VERSION ""

NS_ :

BS_:

BU_: ZCU_F LRCF PAM ZCU_CL
BO_ 1152 FD15_LRCF_DATA_5: 32 LRCF
 SG_ SMARTE_COAST_FR_TAR_DIST : 22|15@0+ (0.0078125,0) [0|255.9921875] "m" ZCU_CL,ZCU_F
 SG_ SMARTE_COAST_FR_TAR_CONFI : 55|2@0+ (1,0) [0|0] "" ZCU_CL,ZCU_F
 SG_ SMARTE_COAST_FR_REL_SPEED : 39|16@0+ (0.00390625,-128) [-128|127.99609375] "m/s" ZCU_CL,ZCU_F

BO_ 897 FD15_LRCF_DATA_6: 64 LRCF
 SG_ FRONT_CAMERA_RIGHTLINE_CURV_DERI : 23|16@0+ (4E-09,-0.000131072) [-0.000131072|0.000131060] "m-2" ZCU_CL
 SG_ FRONT_CAMERA_LEFTLINE_CURV_DERI : 39|16@0+ (4E-09,-0.000131072) [-0.000131072|0.000131060] "m-2" ZCU_CL
 SG_ FRONT_CAMERA_LEFTLINE_DISTANCE : 87|11@0+ (0.016,-16.384) [-16.384|16.336] "m" ZCU_CL
 SG_ FRONT_CAMERA_RIGHTLINE_DISTANCE : 92|11@0+ (0.016,-16.384) [-16.384|16.336] "m" ZCU_CL
 SG_ FRONT_CAMERA_LEFTLINE_CURVATURE : 55|16@0+ (2E-06,-0.065536) [-0.065536|0.065530] "m-1" ZCU_CL
 SG_ FRONT_CAMERA_RIGHTLINE_CURVATURE : 71|16@0+ (2E-06,-0.065536) [-0.065536|0.065530] "m-1" ZCU_CL
 SG_ FRONT_CAMERA_RIGHTLINE_DETECTION : 97|1@0+ (1,0) [0|0] "" ZCU_CL
 SG_ FRONT_CAMERA_LEFTLINE_DETECTION : 96|1@0+ (1,0) [0|0] "" ZCU_CL
 SG_ FRONT_CAMERA_LANE_STATUS : 111|2@0+ (1,0) [0|0] "" ZCU_CL
 SG_ GFHB_CAMERA_STATUS : 109|3@0+ (1,0) [0|0] "" ZCU_CL
 SG_ FRONT_CAM_RIGHT_LINE_TYPE : 106|3@0+ (1,0) [0|0] "" ZCU_CL
 SG_ FRONT_CAM_LEFT_LINE_TYPE : 119|3@0+ (1,0) [0|0] "" ZCU_CL
 SG_ FRONT_CAM_RIGHT_LINE_MARK_QLTY : 116|2@0+ (1,0) [0|0] "" ZCU_CL
 SG_ FRONT_CAM_LEFT_LINE_MARK_QLTY : 114|2@0+ (1,0) [0|0] "" ZCU_CL
 SG_ FRONT_CAM_LEFT_LINE_HEADING_ANG : 112|12@0+ (0.015,-30) [-30|31.425] "Degree" ZCU_CL
 SG_ FRONT_CAM_RIGHT_LINE_HEADING_ANG : 132|12@0+ (0.015,-30) [-30|31.425] "Degree" ZCU_CL
 SG_ FRONT_CAM_LEFT_LINE_VIEW_RNG_ST : 166|7@0+ (0.5,0) [0|63.5] "m" ZCU_CL
 SG_ FRONT_CAM_RIGHT_LINE_VIEW_RNG_ST : 175|7@0+ (0.5,0) [0|63.5] "m" ZCU_CL
 SG_ FRONT_CAM_LEFT_LINE_VIEW_RNG_EN : 136|9@0+ (0.5,0) [0|255.5] "m" ZCU_CL
 SG_ FRONT_CAM_RIGHT_LINE_VIEW_RNG_EN : 159|9@0+ (0.5,0) [0|255.5] "m" ZCU_CL
 SG_ FRONT_CAM_NEXT_LEFT_LINE_TYPE : 283|3@0+ (1,0) [0|0] "" ZCU_CL
 SG_ FRONT_CAM_NEXT_RIGHT_LINE_TYPE : 251|3@0+ (1,0) [0|0] "" ZCU_CL
 SG_ FRONTCAM_NEXTRIGHTLINE_CURV_DERI : 183|16@0+ (4E-09,-0.000131072) [-0.000131072|0.000131060] "m-2" ZCU_CL
 SG_ FRONTCAM_NEXTLEFTLINE_CURV_DERI : 199|16@0+ (4E-09,-0.000131072) [-0.000131072|0.000131060] "m-2" ZCU_CL
 SG_ FRONTCAM_NEXT_LEFTLINE_MARK_QLTY : 289|2@0+ (1,0) [0|0] "" ZCU_CL
 SG_ FRONTCAM_NEXTRIGHTLINE_MARKQLTY : 339|2@0+ (1,0) [0|0] "" ZCU_CL
 SG_ FRONT_CAM_RIGHT_LANE_DIRECTION : 306|2@0+ (1,0) [0|0] "" ZCU_CL
 SG_ FRONT_CAM_LEFT_LANE_DIRECTION : 308|2@0+ (1,0) [0|0] "" ZCU_CL
 SG_ FRONTCAM_NEXT_LEFTLINE_LAT_DIST : 351|6@0+ (0.5,-16) [-16|15.5] "m" ZCU_CL
 SG_ FRONTCAM_NEXT_RIGHTLINE_LAT_DIST : 295|6@0+ (0.5,-16) [-16|15.5] "m" ZCU_CL
 SG_ FRONTCAM_LEFTLINE_LAT_DIST : 329|6@0+ (0.5,-16) [-16|15.5] "m" ZCU_CL
 SG_ FRONTCAM_RIGHTLINE_LAT_DIST : 359|6@0+ (0.5,-16) [-16|15.5] "m" ZCU_CL
 SG_ FRONTCAM_NEXTRIGHTLINE_CURVESTM : 215|16@0+ (2E-06,-0.065536) [-0.065536|0.065530] "m-1" ZCU_CL
 SG_ FRONTCAM_NEXTLEFTLINE_CURVESTIM : 231|16@0+ (2E-06,-0.065536) [-0.065536|0.065530] "m-1" ZCU_CL
 SG_ FRONTCAM_NEXTLEFTLINE_HEAD_ANG : 247|12@0+ (0.015,-30) [-30|31.395] "Degree" ZCU_CL
 SG_ FRONTCAM_NEXTRIGHTLINE_HEAD_ANG : 279|12@0+ (0.015,-30) [-30|31.395] "Degree" ZCU_CL
 SG_ FRONTCAM_NXTLEFTLINE_VIEW_RNG_ST : 367|7@0+ (0.5,0) [0|63.5] "m" ZCU_CL
 SG_ FRONTCAM_NXTRIGHTLINE_VIEWRNG_ST : 391|7@0+ (0.5,0) [0|63.5] "m" ZCU_CL
 SG_ FRONTCAM_NXTLEFTLINE_VIEW_RNG_EN : 399|9@0+ (0.5,0) [0|255.5] "m" ZCU_CL
 SG_ FRONTCAM_NXTRIGHTLINE_VIEWRNG_EN : 495|9@0+ (0.5,0) [0|255.5] "m" ZCU_CL
 SG_ FRONTCAM_NXTLEFTLINE_ROAD_EDGE : 375|3@0+ (1,0) [0|0] "" ZCU_CL
 SG_ FRONTCAM_NXTRIGHTLINE_ROAD_EDGE : 372|3@0+ (1,0) [0|0] "" ZCU_CL
 SG_ FRONTCAM_LEFTLINE_ROAD_EDGE : 383|3@0+ (1,0) [0|0] "" ZCU_CL
 SG_ FRONTCAM_RIGHTLINE_ROAD_EDGE : 380|3@0+ (1,0) [0|0] "" ZCU_CL
 SG_ FRONTCAM_LEFTLANE_DETECTION : 320|1@0+ (1,0) [0|0] "" ZCU_CL
 SG_ FRONTCAM_RIGHTLANE_DETECTION : 312|1@0+ (1,0) [0|0] "" ZCU_CL
 SG_ FRONTCAM_RIGHTHIGHWAY_EXITCONFID : 327|7@0+ (0.01,0) [0|1.27] "%" ZCU_CL
 SG_ FRONTCAM_LEFT_HIGHWAY_EXITCONFID : 319|7@0+ (0.01,0) [0|1.27] "%" ZCU_CL
 SG_ FRONTCAM_LEFT_HIGHWAY_EXIT : 345|2@0+ (1,0) [0|0] "" ZCU_CL
 SG_ FRONTCAM_NXT_LEFTLINE_COLOR : 337|2@0+ (1,0) [0|0] "" ZCU_CL
 SG_ FRONTCAM_NXT_RIGHTTLINE_COLOR : 353|2@0+ (1,0) [0|0] "" ZCU_CL
 SG_ FRONTCAM_LEFTLINE_COLOR : 335|2@0+ (1,0) [0|0] "" ZCU_CL
 SG_ FRONTCAM_RIGHTTLINE_COLOR : 333|2@0+ (1,0) [0|0] "" ZCU_CL
 SG_ FRONTCAM_NXTLEFTLINE_DIST_ACTUAL : 303|11@0+ (0.016,-16.384) [-16.384|16.336] "" ZCU_CL
 SG_ FRONTCAM_NXTRIGHTLINE_DISTACTUAL : 479|11@0+ (0.016,-16.384) [-16.384|16.336] "" ZCU_CL
 SG_ FRONTCAM_NXT_LEFTLINE_DETECT_STS : 280|1@0+ (1,0) [0|0] "" ZCU_CL
 SG_ FRONTCAM_NXTRIGHTLINE_DETECT_STS : 168|1@0+ (1,0) [0|0] "" ZCU_CL
 SG_ FRONTCAM_LANE_CROSSING : 331|2@0+ (1,0) [0|0] "" ZCU_CL
 SG_ FRONTCAM_EGO_OBJ_CIPV : 304|1@0+ (1,0) [0|0] "" ZCU_CL
 SG_ FRONTCAM_EGO2_OBJ_CIPV : 360|1@0+ (1,0) [0|0] "" ZCU_CL
 SG_ FRONTCAM_L1_OBJ_CIPV : 368|1@0+ (1,0) [0|0] "" ZCU_CL
 SG_ FRONTCAM_L2_OBJ_CIPV : 376|1@0+ (1,0) [0|0] "" ZCU_CL
 SG_ FRONTCAM_L3_OBJ_CIPV : 384|1@0+ (1,0) [0|0] "" ZCU_CL
 SG_ FRONTCAM_R1_OBJ_CIPV : 369|1@0+ (1,0) [0|0] "" ZCU_CL
 SG_ FRONTCAM_R2_OBJ_CIPV : 377|1@0+ (1,0) [0|0] "" ZCU_CL
 SG_ FRONTCAM_R3_OBJ_CIPV : 248|1@0+ (1,0) [0|0] "" ZCU_CL
 SG_ FRONTCAM_EGO_OBJ_LONGI_DISTANCE : 415|8@0+ (0.5,0) [0|127.5] "m" ZCU_CL
 SG_ FRONTCAM_EGO2_OBJ_LONGI_DISTANCE : 423|8@0+ (0.5,0) [0|127.5] "m" ZCU_CL
 SG_ FRONTCAM_L1_OBJ_LONGI_DISTANCE : 431|8@0+ (0.5,0) [0|127.5] "m" ZCU_CL
 SG_ FRONTCAM_L2_OBJ_LONGI_DISTANCE : 439|8@0+ (0.5,0) [0|127.5] "m" ZCU_CL
 SG_ FRONTCAM_L3_OBJ_LONGI_DISTANCE : 447|8@0+ (0.5,0) [0|127.5] "m" ZCU_CL
 SG_ FRONTCAM_R1_OBJ_LONGI_DISTANCE : 455|8@0+ (0.5,0) [0|127.5] "m" ZCU_CL
 SG_ FRONTCAM_R2_OBJ_LONGI_DISTANCE : 463|8@0+ (0.5,0) [0|127.5] "m" ZCU_CL
 SG_ FRONTCAM_R3_OBJ_LONGI_DISTANCE : 471|8@0+ (0.5,0) [0|127.5] "m" ZCU_CL
 SG_ FRONTCAM_EGO_OBJ_LAT_REL_SPD : 502|7@0+ (0.5,-32) [-32|31.5] "m/s" ZCU_CL
 SG_ FRONTCAM_EGO2_OBJ_LAT_REL_SPD : 406|7@0+ (0.5,-32) [-32|31.5] "m/s" ZCU_CL
 SG_ FRONTCAM_L1_OBJ_LAT_REL_SPD : 511|7@0+ (0.5,-32) [-32|31.5] "m/s" ZCU_CL

BO_ 640 FD15_LRCF_DATA_7: 64 LRCF
 SG_ VHL_1_CL_SUB_TYPE : 7|4@0+ (1,0) [0|0] "" ZCU_CL
 SG_ VHL_4_CL_SUB_TYPE : 11|4@0+ (1,0) [0|0] "" ZCU_CL
 SG_ VHL_5_CL_SUB_TYPE : 23|4@0+ (1,0) [0|0] "" ZCU_CL
 SG_ VHL_2_CL_SUB_TYPE : 3|4@0+ (1,0) [0|0] "" ZCU_CL
 SG_ VHL_3_CL_SUB_TYPE : 15|4@0+ (1,0) [0|0] "" ZCU_CL
 SG_ VHL_1_TYPE : 19|3@0+ (1,0) [0|0] "" ZCU_CL
 SG_ VHL_2_TYPE : 16|3@0+ (1,0) [0|0] "" ZCU_CL
 SG_ VHL_3_TYPE : 29|3@0+ (1,0) [0|0] "" ZCU_CL
 SG_ VHL_4_TYPE : 26|3@0+ (1,0) [0|0] "" ZCU_CL
 SG_ VHL_5_TYPE : 39|3@0+ (1,0) [0|0] "" ZCU_CL
 SG_ VHL_3_LEFT_ANGLE : 56|14@0+ (0.01,-60) [-60|103.81] "Degree" ZCU_CL
 SG_ VHL_1_LEFT_ANGLE : 36|14@0+ (0.01,-60) [-60|103.81] "Degree" ZCU_CL
 SG_ VHL_2_LEFT_ANGLE : 54|14@0+ (0.01,-60) [-60|103.81] "Degree" ZCU_CL
 SG_ VHL_4_LEFT_ANGLE : 74|14@0+ (0.01,-60) [-60|103.81] "Degree" ZCU_CL
 SG_ VHL_5_LEFT_ANGLE : 92|14@0+ (0.01,-60) [-60|103.81] "Degree" ZCU_CL
 SG_ VHL_1_BOTTOM_ANGLE : 168|14@0+ (0.01,-60) [-60|103.81] "Degree" ZCU_CL
 SG_ VHL_2_BOTTOM_ANGLE : 186|14@0+ (0.01,-60) [-60|103.81] "Degree" ZCU_CL
 SG_ VHL_3_BOTTOM_ANGLE : 204|14@0+ (0.01,-60) [-60|103.81] "Degree" ZCU_CL
 SG_ VHL_4_BOTTOM_ANGLE : 222|14@0+ (0.01,-60) [-60|103.81] "Degree" ZCU_CL
 SG_ VHL_5_BOTTOM_ANGLE : 224|14@0+ (0.01,-60) [-60|103.81] "Degree" ZCU_CL
 SG_ VHL_1_RIGHT_ANGLE : 110|14@0+ (0.01,-60) [-60|103.81] "Degree" ZCU_CL
 SG_ VHL_2_RIGHT_ANGLE : 112|14@0+ (0.01,-60) [-60|103.81] "Degree" ZCU_CL
 SG_ VHL_3_RIGHT_ANGLE : 130|14@0+ (0.01,-60) [-60|103.81] "Degree" ZCU_CL
 SG_ VHL_4_RIGHT_ANGLE : 148|14@0+ (0.01,-60) [-60|103.81] "Degree" ZCU_CL
 SG_ VHL_5_RIGHT_ANGLE : 166|14@0+ (0.01,-60) [-60|103.81] "Degree" ZCU_CL
 SG_ VHL_1_LEFT_DISTANCE : 242|10@0+ (1,2) [2|1023] "m" ZCU_CL
 SG_ VHL_2_LEFT_DISTANCE : 248|10@0+ (1,2) [2|1023] "m" ZCU_CL
 SG_ VHL_3_LEFT_DISTANCE : 270|10@0+ (1,2) [2|1023] "m" ZCU_CL
 SG_ VHL_4_LEFT_DISTANCE : 276|10@0+ (1,2) [2|1023] "m" ZCU_CL
 SG_ VHL_5_LEFT_DISTANCE : 282|10@0+ (1,2) [2|1023] "m" ZCU_CL
 SG_ VHL_1_RIGHT_DISTANCE : 288|10@0+ (1,2) [2|1023] "m" ZCU_CL
 SG_ VHL_2_RIGHT_DISTANCE : 310|10@0+ (1,2) [2|1023] "m" ZCU_CL
 SG_ VHL_3_RIGHT_DISTANCE : 316|10@0+ (1,2) [2|1023] "m" ZCU_CL
 SG_ VHL_4_RIGHT_DISTANCE : 322|10@0+ (1,2) [2|1023] "m" ZCU_CL
 SG_ VHL_5_RIGHT_DISTANCE : 328|10@0+ (1,2) [2|1023] "m" ZCU_CL
 SG_ VHL_1_RIGHT_AZIMUTH_RATE : 350|12@0+ (0.125,-128) [-128|383.625] "Degree/s" ZCU_CL
 SG_ VHL_2_RIGHT_AZIMUTH_RATE : 354|12@0+ (0.125,-128) [-128|383.625] "Degree/s" ZCU_CL
 SG_ VHL_3_RIGHT_AZIMUTH_RATE : 374|12@0+ (0.125,-128) [-128|383.625] "Degree/s" ZCU_CL
 SG_ VHL_4_RIGHT_AZIMUTH_RATE : 378|12@0+ (0.125,-128) [-128|383.625] "Degree/s" ZCU_CL
 SG_ VHL_5_RIGHT_AZIMUTH_RATE : 398|12@0+ (0.125,-128) [-128|383.625] "Degree/s" ZCU_CL
 SG_ VHL_1_LEFT_AZIMUTH_RATE : 402|12@0+ (0.125,-128) [-128|383.625] "Degree/s" ZCU_CL
 SG_ VHL_2_LEFT_AZIMUTH_RATE : 422|12@0+ (0.125,-128) [-128|383.625] "Degree/s" ZCU_CL
 SG_ VHL_3_LEFT_AZIMUTH_RATE : 426|12@0+ (0.125,-128) [-128|383.625] "Degree/s" ZCU_CL

BO_ 642 FD15_LRCF_DATA_8: 64 LRCF
 SG_ TRAFFIC_IS_DETECTED : 261|2@0+ (1,0) [0|0] "" ZCU_CL
 SG_ RFL_1_BRIGHTNESS : 7|7@0+ (0.01,0) [0|1.25] "" ZCU_CL
 SG_ RFL_2_BRIGHTNESS : 0|7@0+ (0.01,0) [0|1.25] "" ZCU_CL
 SG_ RFL_3_BRIGHTNESS : 9|7@0+ (0.01,0) [0|1.25] "" ZCU_CL
 SG_ RFL_1_TOP_ANGLE : 18|11@0+ (0.01,-10) [-10|10.45] "Degree" ZCU_CL
 SG_ RFL_2_TOP_ANGLE : 39|11@0+ (0.01,-10) [-10|10.45] "Degree" ZCU_CL
 SG_ RFL_3_TOP_ANGLE : 44|11@0+ (0.01,-10) [-10|10.45] "Degree" ZCU_CL
 SG_ RFL_1_BOTTOM_ANGLE : 49|11@0+ (0.01,-10) [-10|10.45] "Degree" ZCU_CL
 SG_ RFL_2_BOTTOM_ANGLE : 70|11@0+ (0.01,-10) [-10|10.45] "Degree" ZCU_CL
 SG_ RFL_3_BOTTOM_ANGLE : 75|11@0+ (0.01,-10) [-10|10.45] "Degree" ZCU_CL
 SG_ VHL_1_MIN_DISTANCE : 259|10@0+ (1,2) [2|1023] "m" ZCU_CL
 SG_ VHL_2_MIN_DISTANCE : 265|10@0+ (1,2) [2|1023] "m" ZCU_CL
 SG_ VHL_3_MIN_DISTANCE : 287|10@0+ (1,2) [2|1023] "m" ZCU_CL
 SG_ VHL_4_MIN_DISTANCE : 293|10@0+ (1,2) [2|1023] "m" ZCU_CL
 SG_ VHL_5_MIN_DISTANCE : 299|10@0+ (1,2) [2|1023] "m" ZCU_CL
 SG_ VHL_4_LEFT_AZIMUTH_RATE : 423|12@0+ (0.125,-128) [-128|383.625] "Degree/s" ZCU_CL
 SG_ VHL_5_LEFT_AZIMUTH_RATE : 427|12@0+ (0.125,-128) [-128|383.625] "Degree/s" ZCU_CL
 SG_ RFL_1_RIGHT_ANGLE : 80|13@0+ (0.01,-40) [-40|41.89] "Degree" ZCU_CL
 SG_ RFL_2_RIGHT_ANGLE : 99|13@0+ (0.01,-40) [-40|41.89] "Degree" ZCU_CL
 SG_ RFL_3_RIGHT_ANGLE : 118|13@0+ (0.01,-40) [-40|41.89] "Degree" ZCU_CL
 SG_ RFL_1_LEFT_ANGLE : 121|13@0+ (0.01,-40) [-40|41.89] "Degree" ZCU_CL
 SG_ RFL_2_LEFT_ANGLE : 140|13@0+ (0.01,-40) [-40|41.89] "Degree" ZCU_CL
 SG_ RFL_3_LEFT_ANGLE : 159|13@0+ (0.01,-40) [-40|41.89] "Degree" ZCU_CL
 SG_ RFL_1_LEFT_AZIMUTH_RATE : 193|11@0+ (0.05,-50) [-50|52.25] "Degree/s" ZCU_CL
 SG_ RFL_2_LEFT_AZIMUTH_RATE : 214|11@0+ (0.05,-50) [-50|52.25] "Degree/s" ZCU_CL
 SG_ RFL_3_LEFT_AZIMUTH_RATE : 219|11@0+ (0.05,-50) [-50|52.25] "Degree/s" ZCU_CL
 SG_ RFL_1_RIGHT_AZIMUTH_RATE : 162|11@0+ (0.05,-50) [-50|52.25] "Degree/s" ZCU_CL
 SG_ RFL_2_RIGHT_AZIMUTH_RATE : 183|11@0+ (0.05,-50) [-50|52.25] "Degree/s" ZCU_CL
 SG_ RFL_3_RIGHT_AZIMUTH_RATE : 188|11@0+ (0.05,-50) [-50|52.25] "Degree/s" ZCU_CL
 SG_ RFL_3_DISTANCE : 254|9@0+ (1,0) [0|509] "m" ZCU_CL
 SG_ RFL_2_DISTANCE : 247|9@0+ (1,0) [0|509] "m" ZCU_CL
 SG_ RFL_1_DISTANCE : 224|9@0+ (1,0) [0|509] "m" ZCU_CL
 SG_ VHL_1_VDID : 319|8@0+ (1,0) [0|255] "" ZCU_CL
 SG_ VHL_2_VDID : 327|8@0+ (1,0) [0|255] "" ZCU_CL
 SG_ VHL_3_VDID : 335|8@0+ (1,0) [0|255] "" ZCU_CL
 SG_ VHL_4_VDID : 343|8@0+ (1,0) [0|255] "" ZCU_CL
 SG_ VHL_5_VDID : 351|8@0+ (1,0) [0|255] "" ZCU_CL
 SG_ VHL_1_ID : 359|8@0+ (1,0) [0|255] "" ZCU_CL
 SG_ VHL_2_ID : 367|8@0+ (1,0) [0|255] "" ZCU_CL
 SG_ VHL_3_ID : 375|8@0+ (1,0) [0|255] "" ZCU_CL
 SG_ VHL_4_ID : 383|8@0+ (1,0) [0|255] "" ZCU_CL
 SG_ VHL_5_ID : 391|8@0+ (1,0) [0|255] "" ZCU_CL
 SG_ RFL_1_ID : 399|8@0+ (1,0) [0|255] "" ZCU_CL
 SG_ RFL_2_ID : 407|8@0+ (1,0) [0|255] "" ZCU_CL
 SG_ RFL_3_ID : 415|8@0+ (1,0) [0|255] "" ZCU_CL

BO_ 645 FD15_LRCF_DATA_9: 64 LRCF
 SG_ FREE_4 : 15|4@0+ (1,0) [0|0] "" ZCU_CL
 SG_ ACC_FRONT_TARGET_DISTANCE : 23|15@0+ (0.01,0) [0|327.67] "m" ZCU_CL
 SG_ ACC_ACCEL_SETPOINT_REQ : 24|11@0+ (0.01,-11) [-11|9.47] "m/s2" ZCU_CL
 SG_ ACC_FRONT_TARGET_RELARIVE_ACCEL : 92|12@0+ (0.008,-16) [-16|16.76] "m/s2" ZCU_CL
 SG_ ACC_FRONT_TARGET_RELARIVE_SPEED : 62|14@0+ (0.008,-60) [-60|71.064] "m/s2" ZCU_CL
 SG_ ACC_DESIRED_INTERVEHICLE_DIST : 45|15@0+ (0.008,0) [0|262.128] "m" ZCU_CL
 SG_ ACC_FRONT_TARGET_CRITICITY : 79|7@0+ (0.01,0) [0|1.27] "" ZCU_CL
 SG_ ACC_FRONT_TARGET_POSITION : 87|6@0+ (1,0) [0|0] "" ZCU_CL
 SG_ ACC_FRONT_TARGET_TYPE : 95|3@0+ (1,0) [0|0] "" ZCU_CL
 SG_ E2E_CRC_LRCF_DATA_9 : 7|8@0+ (1,0) [0|0] "-" ZCU_CL
 SG_ E2E_ALIVE_LRCF_DATA_9 : 11|4@0+ (1,0) [0|15] "-" ZCU_CL
 SG_ EGO_LANE_WIDTH : 111|10@0+ (0.01,0) [0|10.23] "m" ZCU_CL
 SG_ EGO_LANE_NUMBER : 141|2@0+ (1,0) [0|0] "" ZCU_CL
 SG_ FRONT_EGO_LANE_LOWER_LIMIT : 117|12@0+ (0.1,0) [0|409.5] "m" ZCU_CL
 SG_ FRONT_EGO_LANE_UPPER_LIMIT : 121|12@0+ (0.1,0) [0|409.5] "m" ZCU_CL
 SG_ EGO_LANE_QUALITY : 139|2@0+ (1,0) [0|0] "" ZCU_CL
 SG_ FRONT_EGO_LANE_A0_POLY_COEF : 137|37@0+ (7.45058E-09,-256) [-256|767.99991795196318] "" ZCU_CL
 SG_ FRONT_EGO_LANE_A1_POLY_COEF : 180|37@0+ (7.45058E-09,-256) [-256|767.99991795196318] "" ZCU_CL
 SG_ FRONT_EGO_LANE_A2_POLY_COEF : 223|37@0+ (7.45058E-09,-256) [-256|767.99991795196318] "" ZCU_CL
 SG_ FRONT_EGO_LANE_A3_POLY_COEF : 279|37@0+ (7.45058E-09,-256) [-256|767.99991795196318] "" ZCU_CL

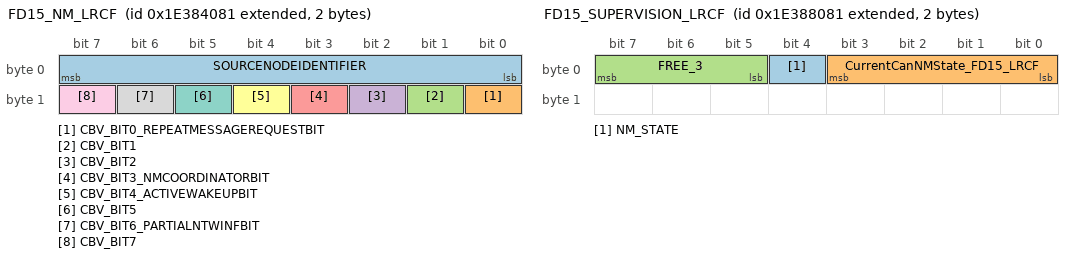
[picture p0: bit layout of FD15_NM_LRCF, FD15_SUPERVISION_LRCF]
BO_ 2654486657 FD15_NM_LRCF: 2 LRCF
 SG_ SOURCENODEIDENTIFIER : 7|8@0+ (1,0) [0|255] "No Unit" ZCU_CL,ZCU_F
 SG_ CBV_BIT0_REPEATMESSAGEREQUESTBIT : 8|1@0+ (1,0) [0|1] "No Unit" ZCU_CL,ZCU_F
 SG_ CBV_BIT1 : 9|1@0+ (1,0) [0|1] "No Unit" ZCU_CL,ZCU_F
 SG_ CBV_BIT2 : 10|1@0+ (1,0) [0|1] "No Unit" ZCU_CL,ZCU_F
 SG_ CBV_BIT3_NMCOORDINATORBIT : 11|1@0+ (1,0) [0|1] "No Unit" ZCU_CL,ZCU_F
 SG_ CBV_BIT4_ACTIVEWAKEUPBIT : 12|1@0+ (1,0) [0|1] "No Unit" ZCU_CL,ZCU_F
 SG_ CBV_BIT5 : 13|1@0+ (1,0) [0|1] "No Unit" ZCU_CL,ZCU_F
 SG_ CBV_BIT6_PARTIALNTWINFBIT : 14|1@0+ (1,0) [0|1] "No Unit" ZCU_CL,ZCU_F
 SG_ CBV_BIT7 : 15|1@0+ (1,0) [0|1] "No Unit" ZCU_CL,ZCU_F

BO_ 282 FD15_ORC_DATA_1: 32 ZCU_CL
 SG_ E2E_ALIVE_ORC_DATA_1_11A : 11|4@0+ (1,0) [0|15] "-" LRCF
 SG_ E2E_CRC_ORC_DATA_1_11A : 7|8@0+ (1,0) [0|0] "-" LRCF
 SG_ LAT_ACCELERATION_FAULT_STS : 50|1@0+ (1,0) [0|0] "" LRCF
 SG_ LONG_ACCELERATION_FAULT_STS : 51|1@0+ (1,0) [0|0] "" LRCF
 SG_ YAW_RATE_FAULT_STS : 49|1@0+ (1,0) [0|0] "" LRCF
 SG_ YAW_RATE : 23|12@0+ (0.08,-163.84) [-163.84|163.68] "Degree/s" LRCF
 SG_ LAT_ACCELERATION : 27|12@0+ (0.02,-40.96) [-40.96|40.92] "m/s2" LRCF
 SG_ LONG_ACCELERATION : 47|12@0+ (0.02,-40.96) [-40.96|40.92] "m/s2" LRCF

BO_ 2654339201 FD15_PDC_INFO_FD_LRCF: 1 LRCF
 SG_ EOL_LRCF : 7|1@0+ (1,0) [0|1] "-" ZCU_CL
 SG_ CurrentCanNMState_FD15_LRCF : 6|4@0+ (1,0) [0|15] "" ZCU_CL

BO_ 2654503041 FD15_SUPERVISION_LRCF: 2 LRCF
 SG_ NM_STATE : 4|1@0+ (1,0) [0|0] "-" ZCU_F
 SG_ CurrentCanNMState_FD15_LRCF : 3|4@0+ (1,0) [0|15] "" ZCU_F
 SG_ FREE_3 : 7|3@0+ (1,0) [0|0] "" ZCU_F

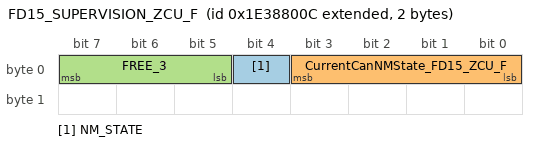
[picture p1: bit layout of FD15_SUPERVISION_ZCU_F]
BO_ 2654502924 FD15_SUPERVISION_ZCU_F: 2 ZCU_F
 SG_ NM_STATE : 4|1@0+ (1,0) [0|0] "-" LRCF,PAM,ZCU_CL
 SG_ CurrentCanNMState_FD15_ZCU_F : 3|4@0+ (1,0) [0|15] "" LRCF,PAM,ZCU_CL
 SG_ FREE_3 : 7|3@0+ (1,0) [0|0] "" LRCF,PAM,ZCU_CL

BO_ 129 FD15_VERS_LRCF: 1 LRCF
 SG_ VERSION_DATA : 7|8@0+ (1,0) [0|255] "" Vector__XXX

BO_ 121 FD15_ZCU_CL_ACK_EVT_DEF: 16 ZCU_CL
 SG_ ECU_Code_ACK : 15|8@0+ (1,0) [0|255] "" LRCF,PAM
 SG_ Rep_UCE : 7|1@0+ (1,0) [0|1] "" LRCF,PAM

BO_ 556 FD15_ZCU_CL_DATA_39: 32 ZCU_CL
 SG_ ACC_STATE_INFO_FOR_CHASSIS : 25|2@0+ (1,0) [0|0] "" LRCF
 SG_ LANE_ASSIT_STATE_FROM_LAS : 28|3@0+ (1,0) [0|0] "" LRCF
 SG_ TORQUE_FACTOR_REQUEST_FROM_LAS : 39|7@0+ (0.01,0) [0|1] "" LRCF
 SG_ YAW_RATE_REQUEST_SETPOINT_LAS : 23|11@0+ (0.05,0) [-50|50] "Degree/s" LRCF
 SG_ PACC_ACCEL_LONGI_REQUEST : 47|10@0+ (0.01,-5) [-5|5.23] "m/s2" LRCF
 SG_ PACC_BEVENT_IN_PROGRESS : 32|1@0+ (1,0) [0|0] "" LRCF

BO_ 1546 FD15_ZCU_CL_DATA_4: 32 ZCU_CL
 SG_ DRIVER_DOOR_OPEN_STATUS : 25|1@0+ (1,0) [0|0] "" LRCF,PAM,ZCU_F
 SG_ EXT_TEMP_FILTRED_DEG_C : 23|10@0+ (0.5,-85) [-85|425.5] "Degree C" LRCF,PAM,ZCU_F
 SG_ HEADLAMP_WITH_WIPER_REQ : 27|1@0+ (1,0) [0|0] "" LRCF,PAM,ZCU_F
 SG_ TRAILER_CONNECTION_STS : 29|2@0+ (1,0) [0|0] "" LRCF,PAM,ZCU_F
 SG_ RCTA_DRIVER_INHIBITION_REQUEST : 24|1@0+ (1,0) [0|0] "" LRCF,PAM,ZCU_F
 SG_ PASSENGER_DOOR_OPEN_STATUS : 26|1@0+ (1,0) [0|0] "" LRCF,PAM,ZCU_F
 SG_ TURN_SIGNAL_STS : 38|2@0+ (1,0) [0|0] "" LRCF,PAM,ZCU_F
 SG_ DAY_NIGHT_STATUS : 39|1@0+ (1,0) [0|0] "" LRCF,PAM,ZCU_F
 SG_ FRONT_WIPING_ST : 35|5@0+ (1,0) [0|0] "" LRCF,PAM,ZCU_F
 SG_ FRT_WIPING_CONF : 46|1@0+ (1,0) [0|0] "" LRCF,PAM,ZCU_F
 SG_ DRIVING_MODE_POWERTRAIN_REQ : 45|5@0+ (1,0) [0|0] "" LRCF,PAM,ZCU_F

BO_ 1032 FD15_ZCU_CL_DATA_7: 32 ZCU_CL
 SG_ DRIVER_SEATBELT_BUCKLE_DATA : 23|1@0+ (1,0) [0|0] "" LRCF,PAM
 SG_ DRIVER_SEATBELT_BUCKLE_SECU_DATA : 22|2@0+ (1,0) [0|0] "" LRCF,PAM
 SG_ ROW1_P_SEATBELT_BUCKLE_DATA : 20|1@0+ (1,0) [0|0] "" LRCF,PAM
 SG_ ROW1_P_SEATBELT_BUCKLE_SECU_DATA : 19|2@0+ (1,0) [0|0] "" LRCF,PAM
 SG_ TURN_INDICATOR_DRIVER_DMD : 17|2@0+ (1,0) [0|0] "" LRCF,PAM
 SG_ VIN_INFORMATION : 31|136@0+ (1,0) [0|0] "" LRCF,PAM

BO_ 1289 FD15_ZCU_CL_DATA_9: 32 ZCU_CL
 SG_ BLINDSPOTDETECTION_DRIVERREQUEST : 23|1@0+ (1,0) [0|0] "" LRCF,PAM

BO_ 1034 FD15_ZCU_CL_GLOBAL_DATA_1: 32 ZCU_CL
 SG_ FREE_4 : 15|4@0+ (1,0) [0|0] "" LRCF,PAM
 SG_ VEHICLE_IGNITION_STATUS : 23|3@0+ (1,0) [0|0] "" LRCF,PAM
 SG_ PROPULSION_OFF_REQUEST : 20|1@0+ (1,0) [0|0] "" LRCF,PAM
 SG_ VEHICLE_MODE_CONFIGURATION : 19|4@0+ (1,0) [0|0] "" LRCF,PAM
 SG_ E2E_CRC_ZCU_CL_GLOBAL_DATA_40A : 7|8@0+ (1,0) [0|0] "-" LRCF,PAM
 SG_ E2E_ALIVE_ZCU_CL_GLOBAL_DATA_40A : 11|4@0+ (1,0) [0|15] "-" LRCF,PAM
 SG_ DAY_LIGHT_MODE_CMD : 39|1@0+ (1,0) [0|0] "" LRCF,PAM
 SG_ BACK_LIGHT_INTENSITY_CMD : 31|8@0+ (0.5,0) [0|127.5] "%" LRCF,PAM

BO_ 1550 FD15_ZCU_F_DATA_15: 32 ZCU_F
 SG_ ESC_TCS_FAILSTATUS : 23|1@0+ (1,0) [0|0] "" LRCF
 SG_ FREE_4 : 15|4@0+ (1,0) [0|0] "" LRCF
 SG_ WHEEL_SPARE_SIZEDETECTION_STATE : 22|1@0+ (1,0) [0|0] "" LRCF
 SG_ E2E_CRC_ZCU_F_DATA_15 : 7|8@0+ (1,0) [0|0] "-" LRCF
 SG_ E2E_ALIVE_ZCU_F_DATA_15 : 11|4@0+ (1,0) [0|15] "" LRCF

BO_ 1055 FD15_ZCU_F_DATA_17: 32 ZCU_F
 SG_ HOD_FAIL_STATUS : 23|2@0+ (1,0) [0|0] "" LRCF
 SG_ STEERWHEEL_HELD_BY_DRIVER_OPTI : 21|1@0+ (1,0) [0|0] "" LRCF

BO_ 270 FD15_ZCU_F_DATA_9: 32 ZCU_F
 SG_ FREE_4 : 15|4@0+ (1,0) [0|0] "" LRCF,PAM,ZCU_CL
 SG_ ACCEL_PEDAL_PERCENT_PWT : 23|8@0+ (0.4,0) [0|101.6] "%" LRCF,PAM,ZCU_CL
 SG_ PRND_ENGAGED_FOR_DISPLAY : 100|5@0+ (1,0) [0|0] "" LRCF,PAM,ZCU_CL
 SG_ PRND_TARGET_STATE : 91|4@0+ (1,0) [0|0] "" LRCF,PAM,ZCU_CL
 SG_ SHIFT_LEVER_POSITION_PWT : 31|4@0+ (1,0) [0|0] "" LRCF,PAM,ZCU_CL
 SG_ E2E_CRC_ZCU_F_DATA_9 : 7|8@0+ (1,0) [0|0] "-" LRCF,PAM,ZCU_CL
 SG_ E2E_ALIVE_ZCU_F_DATA_9 : 11|4@0+ (1,0) [0|15] "-" LRCF,PAM,ZCU_CL
 SG_ HANDWHEEL_STEERING_ANGLE_VALUE_S : 47|14@0+ (0.1,-820) [-820|818.2] "Degree" LRCF,PAM,ZCU_CL
 SG_ LXA_STEERING_STATE_S : 49|2@0+ (1,0) [0|0] "" LRCF,PAM,ZCU_CL
 SG_ STEERING_ASSIST_STATUS_S : 94|3@0+ (1,0) [0|0] "" LRCF,PAM,ZCU_CL
 SG_ STEERINGWHEEL_ANGLE_REL_FRT_VA_S : 63|15@0+ (0.1,-1638) [-1638|1638.6] "Degree" LRCF,PAM,ZCU_CL
 SG_ STEERINGWHEEL_ROT_VELOCITY_FRT_S : 27|12@0+ (1,-2050) [-2050|2044] "Degree/s" LRCF,PAM,ZCU_CL
 SG_ ACC_STATE_INFO_IN_POWERTRAIN : 103|3@0+ (1,0) [0|0] "" LRCF,PAM,ZCU_CL
 SG_ STEERINGWHEEL_ANGLE_FRONT_VAL_S : 79|14@0+ (0.1,-820) [-820|818.2] "Degree" LRCF,PAM,ZCU_CL
 SG_ CRUISE_CONTROL_STATUS : 111|3@0+ (1,0) [0|7] "" LRCF,PAM,ZCU_CL

BO_ 1035 FD15_ZCU_F_GLOBAL_DATA_2: 32 ZCU_F
 SG_ FREE_4 : 15|4@0+ (1,0) [0|0] "" LRCF,PAM
 SG_ PROPULSION_SYSTEM_ACTIVE : 47|1@0+ (1,0) [0|0] "" LRCF,PAM
 SG_ E2E_CRC_ZCU_F_GLOBAL_DATA : 7|8@0+ (1,0) [0|0] "-" LRCF,PAM
 SG_ E2E_ALIVE_ZCU_F_GLOBAL_DATA_40B : 11|4@0+ (1,0) [0|15] "-" LRCF,PAM
 SG_ TOTAL_ODOMETER : 23|24@0+ (0.1,0) [0|1677721.4] "km" LRCF,PAM
 SG_ DIAGMUX : 46|1@0+ (1,0) [0|0] "" LRCF,PAM
 SG_ TRUSTED_TIME_YEAR : 55|16@0+ (1,0) [0|65534] "Year" LRCF,PAM
 SG_ TRUSTED_TIME_MONTH : 71|4@0+ (1,1) [1|15] "month" LRCF,PAM
 SG_ TRUSTED_TIME_DAY : 79|5@0+ (1,1) [1|31] "day" LRCF,PAM
 SG_ TRUSTED_TIME_HOUR : 87|5@0+ (1,0) [0|30] "hour" LRCF,PAM
 SG_ TRUSTED_TIME_MINUTE : 45|6@0+ (1,0) [0|62] "min" LRCF,PAM
 SG_ TRUSTED_TIME_SECOND : 95|6@0+ (1,0) [0|62] "" LRCF,PAM
 SG_ SHUTDOWN_NTW_FD_CAN14 : 67|1@0+ (1,0) [0|0] "" Vector__XXX
 SG_ SHUTDOWN_NTW_FD_CAN5 : 66|1@0+ (1,0) [0|0] "" Vector__XXX

CM_ SG_ 1152 SMARTE_COAST_FR_TAR_DIST "Longitudinal distance of the Ecaosting target in the host vehicle's coordinate system";
CM_ SG_ 1152 SMARTE_COAST_FR_TAR_CONFI "Confidence of Ecaosting target.";
CM_ SG_ 1152 SMARTE_COAST_FR_REL_SPEED "Relative longitudinal velocity of the Ecaosting target in the host vehicle's coordinate system.";
CM_ SG_ 897 FRONT_CAMERA_RIGHTLINE_CURV_DERI "Curvature derivative of right lane marking";
CM_ SG_ 897 FRONT_CAMERA_LEFTLINE_CURV_DERI "Curvature derivative of left lane marking";
CM_ SG_ 897 FRONT_CAMERA_RIGHTLINE_DETECTION "Validity-flag for detection of the road's right line  according to line history, contrast, lane coherence,  view range, camera-state and lane width changes";
CM_ SG_ 897 FRONT_CAMERA_LEFTLINE_DETECTION "Validity-flag for detection of the road's left line  according to line history, contrast, lane coherence,  view range, camera-state and lane width changes";
CM_ SG_ 897 FRONT_CAMERA_LANE_STATUS "Overall status of the FrontCamera 
(fully operational, blocked, degraded, defect)";
CM_ SG_ 897 GFHB_CAMERA_STATUS "Defines the status of  GFHB function";
CM_ SG_ 897 FRONT_CAM_RIGHT_LINE_MARK_QLTY "Quality of right host lane’s line marking";
CM_ SG_ 897 FRONT_CAM_LEFT_LINE_MARK_QLTY "Quality of left host lane’s line marking";
CM_ SG_ 897 FRONT_CAM_NEXT_LEFT_LINE_TYPE "This signal indicates the type of the next left ego line marking";
CM_ SG_ 897 FRONT_CAM_NEXT_RIGHT_LINE_TYPE "This signal indicates the type of the next right ego line marking";
CM_ SG_ 897 FRONTCAM_NEXTRIGHTLINE_CURV_DERI "Derivative of left line marking curvature  (Polynomial C3, unit: 1/m^2)";
CM_ SG_ 897 FRONTCAM_NEXTLEFTLINE_CURV_DERI "Derivative of left line marking curvature  (Polynomial C3, unit: 1/m^2)";
CM_ SG_ 897 FRONTCAM_NEXT_LEFTLINE_MARK_QLTY "Quality of next right host lane’s line marking";
CM_ SG_ 897 FRONTCAM_NEXTRIGHTLINE_MARKQLTY "Quality of next right host lane’s line marking";
CM_ SG_ 897 FRONT_CAM_RIGHT_LANE_DIRECTION "This signal indicates the direction of the right lane";
CM_ SG_ 897 FRONT_CAM_LEFT_LANE_DIRECTION "This signal indicates the direction of the right lane";
CM_ SG_ 897 FRONTCAM_NEXT_LEFTLINE_LAT_DIST "Lateral distance of the next left (considering the inner part of the line) line with respect to the Forward-Facing Camera coordinate system";
CM_ SG_ 897 FRONTCAM_NEXT_RIGHTLINE_LAT_DIST "Lateral distance of the next right (considering the inner part of the line) line with respect to the Forward-Facing Camera coordinate system";
CM_ SG_ 897 FRONTCAM_LEFTLINE_LAT_DIST "Lateral distance of the first left (considering the inner part of the line) line with respect to the Forward-Facing Camera coordinate system";
CM_ SG_ 897 FRONTCAM_RIGHTLINE_LAT_DIST "Lateral distance of the first right (considering the inner part of the line) line with respect to the Forward-Facing Camera coordinate system";
CM_ SG_ 897 FRONTCAM_NEXTRIGHTLINE_CURVESTM "Estimated curvature of next right line marking (Polynomial C2, unit: 1/m)";
CM_ SG_ 897 FRONTCAM_NEXTLEFTLINE_CURVESTIM "Estimated curvature of next left line marking (Polynomial C2, unit: 1/m)";
CM_ SG_ 897 FRONTCAM_NEXTLEFTLINE_HEAD_ANG "C1: Heading angle of vehicle with the  next left line (angle between vehicle direction and lane limit direction, unit: ° (deg))";
CM_ SG_ 897 FRONTCAM_NEXTRIGHTLINE_HEAD_ANG "C1: Heading angle of vehicle with the  next left line (angle between vehicle direction and lane limit direction, unit: ° (deg))";
CM_ SG_ 897 FRONTCAM_NXTLEFTLINE_VIEW_RNG_ST "Next left host lane’s line marking View Range starts at this distance";
CM_ SG_ 897 FRONTCAM_NXTRIGHTLINE_VIEWRNG_ST "Next right Left host lane’s line marking View Range starts at this distance";
CM_ SG_ 897 FRONTCAM_NXTLEFTLINE_VIEW_RNG_EN "Next left host lane’s line marking View Range ends at this distance";
CM_ SG_ 897 FRONTCAM_NXTRIGHTLINE_VIEWRNG_EN "Next right Left host lane’s line marking View Range ends at this distance";
CM_ SG_ 897 FRONTCAM_NXTLEFTLINE_ROAD_EDGE "Next Left Line roadedge  :  Flat =  transition from asphalt to grass or gravel Elevated_Structure =Higher objects like road bariers) Curb : Generally curbs with different colors and sizes Cones_poles : All kinds of road cones Parking_cars=Cars parked in a line on the side of the road No_Roadedge";
CM_ SG_ 897 FRONTCAM_NXTRIGHTLINE_ROAD_EDGE "Next Right Line roadedge  :  Flat =  transition from asphalt to grass or gravel Elevated_Structure =Higher objects like road bariers) Curb : Generally curbs with different colors and sizes Cones_poles : All kinds of road cones Parking_cars=Cars parked in a line on the side of the road No_Roadedge";
CM_ SG_ 897 FRONTCAM_LEFTLINE_ROAD_EDGE "Left Line roadedge  :  Flat =  transition from asphalt to grass or gravel Elevated_Structure =Higher objects like road bariers) Curb : Generally curbs with different colors and sizes Cones_poles : All kinds of road cones Parking_cars=Cars parked in a line on the side of the road No_Roadedge";
CM_ SG_ 897 FRONTCAM_RIGHTLINE_ROAD_EDGE "Right Line roadedge  :  Flat =  transition from asphalt to grass or gravel Elevated_Structure =Higher objects like road bariers) Curb : Generally curbs with different colors and sizes Cones_poles : All kinds of road cones Parking_cars=Cars parked in a line on the side of the road No_Roadedge";
CM_ SG_ 897 FRONTCAM_LEFTLANE_DETECTION "This signal indicates if a lane  is detected at the left of the host vehicle.";
CM_ SG_ 897 FRONTCAM_RIGHTLANE_DETECTION "This signal indicates if a lane  is detected at the right of the host vehicle.";
CM_ SG_ 897 FRONTCAM_RIGHTHIGHWAY_EXITCONFID "Confidence of detection of left highway exit";
CM_ SG_ 897 FRONTCAM_LEFT_HIGHWAY_EXITCONFID "Confidence of detection of left highway exit";
CM_ SG_ 897 FRONTCAM_LEFT_HIGHWAY_EXIT "Highway exit (HWE) can only be detected on one side at a time";
CM_ SG_ 897 FRONTCAM_NXT_LEFTLINE_COLOR "Color of the Next Left line";
CM_ SG_ 897 FRONTCAM_NXT_RIGHTTLINE_COLOR "Color of the Next right line";
CM_ SG_ 897 FRONTCAM_LEFTLINE_COLOR "Color of the Next right line";
CM_ SG_ 897 FRONTCAM_RIGHTTLINE_COLOR "Color of the right line";
CM_ SG_ 897 FRONTCAM_NXTLEFTLINE_DIST_ACTUAL "Front camera center to inner edge next left line (C0 parameter of line equation)";
CM_ SG_ 897 FRONTCAM_NXTRIGHTLINE_DISTACTUAL "Distance: Center of the vehicle to inner edge  of the road's next right line (Polynomial C0)";
CM_ SG_ 897 FRONTCAM_NXT_LEFTLINE_DETECT_STS "Validity-flag for detection of the road's next left line  according to line history, contrast, lane coherence,  view range, camera-state and lane width changes";
CM_ SG_ 897 FRONTCAM_NXTRIGHTLINE_DETECT_STS "Validity-flag for detection of the road's next right line  according to line history, contrast, lane coherence,  view range, camera-state and lane width changes";
CM_ SG_ 897 FRONTCAM_LANE_CROSSING "This flow indicates if the ego change the lane on the left or right side.";
CM_ SG_ 897 FRONTCAM_EGO_OBJ_CIPV "This is the boolean flag that indicates which target the ACC feature reacts to. (four target could be considered 1st front, 2nd front 3rd or 4th while using overtake aid)";
CM_ SG_ 897 FRONTCAM_EGO2_OBJ_CIPV "This is the boolean flag that indicates which target the ACC feature reacts to. (four target could be considered 1st front, 2nd front 3rd or 4th while using overtake aid)";
CM_ SG_ 897 FRONTCAM_L1_OBJ_CIPV "This is the boolean flag that indicates which target the ACC feature reacts to. (four target could be considered 1st front, 2nd front 3rd or 4th while using overtake aid)";
CM_ SG_ 897 FRONTCAM_L2_OBJ_CIPV "This is the boolean flag that indicates which target the ACC feature reacts to. (four target could be considered 1st front, 2nd front 3rd or 4th while using overtake aid)";
CM_ SG_ 897 FRONTCAM_L3_OBJ_CIPV "This is the boolean flag that indicates which target the ACC feature reacts to. (four target could be considered 1st front, 2nd front 3rd or 4th while using overtake aid)";
CM_ SG_ 897 FRONTCAM_R1_OBJ_CIPV "This is the boolean flag that indicates which target the ACC feature reacts to. (four target could be considered 1st front, 2nd front 3rd or 4th while using overtake aid)";
CM_ SG_ 897 FRONTCAM_R2_OBJ_CIPV "This is the boolean flag that indicates which target the ACC feature reacts to. (four target could be considered 1st front, 2nd front 3rd or 4th while using overtake aid)";
CM_ SG_ 897 FRONTCAM_R3_OBJ_CIPV "This is the boolean flag that indicates which target the ACC feature reacts to. (four target could be considered 1st front, 2nd front 3rd or 4th while using overtake aid)";
CM_ SG_ 897 FRONTCAM_EGO_OBJ_LONGI_DISTANCE "Longitudinal distance of the ego objects target with respect to the Forward-Facing Camera coordinate system";
CM_ SG_ 897 FRONTCAM_EGO2_OBJ_LONGI_DISTANCE "Longitudinal distance of the second ego objects target  with respect to the Forward-Facing Camera coordinate system";
CM_ SG_ 897 FRONTCAM_L1_OBJ_LONGI_DISTANCE "Longitudinal distance of the first target on the left side lane  with respect to the Forward-Facing Camera coordinate system";
CM_ SG_ 897 FRONTCAM_L2_OBJ_LONGI_DISTANCE "Longitudinal distance of second target on the left side lane with respect to the Forward-Facing Camera coordinate system";
CM_ SG_ 897 FRONTCAM_L3_OBJ_LONGI_DISTANCE "Longitudinal distance third target on the left side lane with respect to the Forward-Facing Camera coordinate system";
CM_ SG_ 897 FRONTCAM_R1_OBJ_LONGI_DISTANCE "Longitudinal distance of the first target on the right side lane  with respect to the Forward-Facing Camera coordinate system";
CM_ SG_ 897 FRONTCAM_R2_OBJ_LONGI_DISTANCE "Longitudinal distance of the second target on the right side lane  with respect to the Forward-Facing Camera coordinate system";
CM_ SG_ 897 FRONTCAM_R3_OBJ_LONGI_DISTANCE "Longitudinal distance third target on the right side lane with respect to the Forward-Facing Camera coordinate system";
CM_ SG_ 897 FRONTCAM_EGO_OBJ_LAT_REL_SPD "Relative lateral velocity of Measured Target Front with respect to host vehicle";
CM_ SG_ 897 FRONTCAM_EGO2_OBJ_LAT_REL_SPD "Relative lateral velocity of Measured Second Target Front with respect to host vehicle";
CM_ SG_ 897 FRONTCAM_L1_OBJ_LAT_REL_SPD "Relative lateral velocity of Measured Target L1 Front with respect to host vehicle";
CM_ SG_ 640 VHL_1_CL_SUB_TYPE "ENUM describes cluster sub type. If not cluster = 0
Indicates if the cluster of vehicles is mixing oncoming and/or leading vehicles, or not.
INVALID : object is not a cluster
ONCOMING : All objects are oncoming
TAILLIGHT : All objects are leading
LEFT_ONCOMING: Most left object is oncoming, others are leading.
RIGHT_ONCOMING: Most right object is oncoming, others are leading.
LEFT_AND_RIGHT_ONCOMING: Leading objects between most left and right.
LEFT_AND_RIGHT_TAILLIGHT: Oncoming objects between most left and right.
Invalid
Unavailable";
CM_ SG_ 640 VHL_4_CL_SUB_TYPE "ENUM describes cluster sub type. If not cluster = 0
Indicates if the cluster of vehicles is mixing oncoming and/or leading vehicles, or not.
INVALID : object is not a cluster
ONCOMING : All objects are oncoming
TAILLIGHT : All objects are leading
LEFT_ONCOMING: Most left object is oncoming, others are leading.
RIGHT_ONCOMING: Most right object is oncoming, others are leading.
LEFT_AND_RIGHT_ONCOMING: Leading objects between most left and right.
LEFT_AND_RIGHT_TAILLIGHT: Oncoming objects between most left and right.
Invalid
Unavailable";
CM_ SG_ 640 VHL_5_CL_SUB_TYPE "ENUM describes cluster sub type. If not cluster = 0
Indicates if the cluster of vehicles is mixing oncoming and/or leading vehicles, or not.
INVALID : object is not a cluster
ONCOMING : All objects are oncoming
TAILLIGHT : All objects are leading
LEFT_ONCOMING: Most left object is oncoming, others are leading.
RIGHT_ONCOMING: Most right object is oncoming, others are leading.
LEFT_AND_RIGHT_ONCOMING: Leading objects between most left and right.
LEFT_AND_RIGHT_TAILLIGHT: Oncoming objects between most left and right.
Invalid
Unavailable";
CM_ SG_ 640 VHL_2_CL_SUB_TYPE "ENUM describes cluster sub type. If not cluster = 0
Indicates if the cluster of vehicles is mixing oncoming and/or leading vehicles, or not.
INVALID : object is not a cluster
ONCOMING : All objects are oncoming
TAILLIGHT : All objects are leading
LEFT_ONCOMING: Most left object is oncoming, others are leading.
RIGHT_ONCOMING: Most right object is oncoming, others are leading.
LEFT_AND_RIGHT_ONCOMING: Leading objects between most left and right.
LEFT_AND_RIGHT_TAILLIGHT: Oncoming objects between most left and right.
Invalid
Unavailable";
CM_ SG_ 640 VHL_3_CL_SUB_TYPE "ENUM describes cluster sub type. If not cluster = 0
Indicates if the cluster of vehicles is mixing oncoming and/or leading vehicles, or not.
INVALID : object is not a cluster
ONCOMING : All objects are oncoming
TAILLIGHT : All objects are leading
LEFT_ONCOMING: Most left object is oncoming, others are leading.
RIGHT_ONCOMING: Most right object is oncoming, others are leading.
LEFT_AND_RIGHT_ONCOMING: Leading objects between most left and right.
LEFT_AND_RIGHT_TAILLIGHT: Oncoming objects between most left and right.
Invalid
Unavailable";
CM_ SG_ 640 VHL_1_TYPE "Describes the vehicle light type detected. Indicates oncoming or leading vehicle  In case of a cluster it represents the type of the closest vehicle in the cluster. Clearance = Truck cabin top lights (i.e. oncoming).";
CM_ SG_ 640 VHL_2_TYPE "Describes the vehicle light type detected. Indicates oncoming or leading vehicle  In case of a cluster it represents the type of the closest vehicle in the cluster. Clearance = Truck cabin top lights (i.e. oncoming).";
CM_ SG_ 640 VHL_3_TYPE "Describes the vehicle light type detected. Indicates oncoming or leading vehicle  In case of a cluster it represents the type of the closest vehicle in the cluster. Clearance = Truck cabin top lights (i.e. oncoming).";
CM_ SG_ 640 VHL_4_TYPE "Describes the vehicle light type detected. Indicates oncoming or leading vehicle  In case of a cluster it represents the type of the closest vehicle in the cluster. Clearance = Truck cabin top lights (i.e. oncoming).";
CM_ SG_ 640 VHL_5_TYPE "Describes the vehicle light type detected. Indicates oncoming or leading vehicle  In case of a cluster it represents the type of the closest vehicle in the cluster. Clearance = Truck cabin top lights (i.e. oncoming).";
CM_ SG_ 640 VHL_3_LEFT_ANGLE "Horizontal angle at the Left tail light or headlamp of vehicle detected at the extreme Left of the cluster (oncoming or leading), by a camera having at least +/-50deg of horizontal field of view. This angle is calculated from the camera reference.";
CM_ SG_ 640 VHL_1_LEFT_ANGLE "Horizontal angle at the Left tail light or headlamp of vehicle detected at the extreme Left of the cluster (oncoming or leading), by a camera having at least +/-50deg of horizontal field of view. This angle is calculated from the camera reference.";
CM_ SG_ 640 VHL_2_LEFT_ANGLE "Horizontal angle at the Left tail light or headlamp of vehicle detected at the extreme Left of the cluster (oncoming or leading), by a camera having at least +/-50deg of horizontal field of view. This angle is calculated from the camera reference.";
CM_ SG_ 640 VHL_4_LEFT_ANGLE "Horizontal angle at the Left tail light or headlamp of vehicle detected at the extreme Left of the cluster (oncoming or leading), by a camera having at least +/-50deg of horizontal field of view. This angle is calculated from the camera reference.";
CM_ SG_ 640 VHL_5_LEFT_ANGLE "Horizontal angle at the Left tail light or headlamp of vehicle detected at the extreme Left of the cluster (oncoming or leading), by a camera having at least +/-50deg of horizontal field of view. This angle is calculated from the camera reference.";
CM_ SG_ 640 VHL_1_BOTTOM_ANGLE "Vertical Angle to bottom of the closest / lowest vehicle lights in the cluster rectangle including object lights. This angle is calculated from the camera reference.";
CM_ SG_ 640 VHL_2_BOTTOM_ANGLE "Vertical Angle to bottom of the closest / lowest vehicle lights in the cluster rectangle including object lights. This angle is calculated from the camera reference.";
CM_ SG_ 640 VHL_3_BOTTOM_ANGLE "Vertical Angle to bottom of the closest / lowest vehicle lights in the cluster rectangle including object lights. This angle is calculated from the camera reference.";
CM_ SG_ 640 VHL_4_BOTTOM_ANGLE "Vertical Angle to bottom of the closest / lowest vehicle lights in the cluster rectangle including object lights. This angle is calculated from the camera reference.";
CM_ SG_ 640 VHL_5_BOTTOM_ANGLE "Vertical Angle to bottom of the closest / lowest vehicle lights in the cluster rectangle including object lights. This angle is calculated from the camera reference.";
CM_ SG_ 640 VHL_1_RIGHT_ANGLE "Horizontal angle at the Right tail light or headlamp of vehicle detected at the extreme Right of the cluster (oncoming or leading), by a camera having at least +/-50deg of horizontal field of view. This angle is calculated from the camera reference.";
CM_ SG_ 640 VHL_2_RIGHT_ANGLE "Horizontal angle at the Right tail light or headlamp of vehicle detected at the extreme Right of the cluster (oncoming or leading), by a camera having at least +/-50deg of horizontal field of view. This angle is calculated from the camera reference.";
CM_ SG_ 640 VHL_3_RIGHT_ANGLE "Horizontal angle at the Right tail light or headlamp of vehicle detected at the extreme Right of the cluster (oncoming or leading), by a camera having at least +/-50deg of horizontal field of view. This angle is calculated from the camera reference.";
CM_ SG_ 640 VHL_4_RIGHT_ANGLE "Horizontal angle at the Right tail light or headlamp of vehicle detected at the extreme Right of the cluster (oncoming or leading), by a camera having at least +/-50deg of horizontal field of view. This angle is calculated from the camera reference.";
CM_ SG_ 640 VHL_5_RIGHT_ANGLE "Horizontal angle at the Right tail light or headlamp of vehicle detected at the extreme Right of the cluster (oncoming or leading), by a camera having at least +/-50deg of horizontal field of view. This angle is calculated from the camera reference.";
CM_ SG_ 640 VHL_1_LEFT_DISTANCE "Horizontal minimum distance to the extreme left vehicle detected in the cluster 2.";
CM_ SG_ 640 VHL_2_LEFT_DISTANCE "Horizontal minimum distance to the extreme left vehicle detected in the cluster 2.";
CM_ SG_ 640 VHL_3_LEFT_DISTANCE "Horizontal minimum distance to the extreme left vehicle detected in the cluster 2.";
CM_ SG_ 640 VHL_4_LEFT_DISTANCE "Horizontal minimum distance to the extreme left vehicle detected in the cluster 2.";
CM_ SG_ 640 VHL_5_LEFT_DISTANCE "Horizontal minimum distance to the extreme left vehicle detected in the cluster 2.";
CM_ SG_ 640 VHL_1_RIGHT_DISTANCE "Horizontal minimum distance to the extreme Right vehicle detected in the cluster 1.";
CM_ SG_ 640 VHL_2_RIGHT_DISTANCE "Horizontal minimum distance to the extreme Right vehicle detected in the cluster 1.";
CM_ SG_ 640 VHL_3_RIGHT_DISTANCE "Horizontal minimum distance to the extreme Right vehicle detected in the cluster 1.";
CM_ SG_ 640 VHL_4_RIGHT_DISTANCE "Horizontal minimum distance to the extreme Right vehicle detected in the cluster 1.";
CM_ SG_ 640 VHL_5_RIGHT_DISTANCE "Horizontal minimum distance to the extreme Right vehicle detected in the cluster 1.";
CM_ SG_ 640 VHL_1_RIGHT_AZIMUTH_RATE "Horizontal relative azimuth angular velocity of the Right side of vehicle detected at the extreme Left of the cluster. It is calculated in the camera coordinates system. The ego-vehicle yaw rate value is deducted from the measured relative azimuth rate value and then shall be added downstream.  Due to this, the signal is not strictly, a derivative of the corresponding angular coordinate.";
CM_ SG_ 640 VHL_2_RIGHT_AZIMUTH_RATE "Horizontal relative azimuth angular velocity of the Right side of vehicle detected at the extreme Left of the cluster. It is calculated in the camera coordinates system. The ego-vehicle yaw rate value is deducted from the measured relative azimuth rate value and then shall be added downstream.  Due to this, the signal is not strictly, a derivative of the corresponding angular coordinate.";
CM_ SG_ 640 VHL_3_RIGHT_AZIMUTH_RATE "Horizontal relative azimuth angular velocity of the Right side of vehicle detected at the extreme Left of the cluster. It is calculated in the camera coordinates system. The ego-vehicle yaw rate value is deducted from the measured relative azimuth rate value and then shall be added downstream.  Due to this, the signal is not strictly, a derivative of the corresponding angular coordinate.";
CM_ SG_ 640 VHL_4_RIGHT_AZIMUTH_RATE "Horizontal relative azimuth angular velocity of the Right side of vehicle detected at the extreme Left of the cluster. It is calculated in the camera coordinates system. The ego-vehicle yaw rate value is deducted from the measured relative azimuth rate value and then shall be added downstream.  Due to this, the signal is not strictly, a derivative of the corresponding angular coordinate.";
CM_ SG_ 640 VHL_5_RIGHT_AZIMUTH_RATE "Horizontal relative azimuth angular velocity of the Right side of vehicle detected at the extreme Left of the cluster. It is calculated in the camera coordinates system. The ego-vehicle yaw rate value is deducted from the measured relative azimuth rate value and then shall be added downstream.  Due to this, the signal is not strictly, a derivative of the corresponding angular coordinate.";
CM_ SG_ 640 VHL_1_LEFT_AZIMUTH_RATE "Horizontal relative azimuth angular velocity of the Left side of vehicle detected at the extreme Left of the cluster. It is calculated in the camera coordinates system. The ego-vehicle yaw rate value is deducted from the measured relative azimuth rate value and then shall be added downstream.  Due to this, the signal is not strictly, a derivative of the corresponding angular coordinate.";
CM_ SG_ 640 VHL_2_LEFT_AZIMUTH_RATE "Horizontal relative azimuth angular velocity of the Left side of vehicle detected at the extreme Left of the cluster. It is calculated in the camera coordinates system. The ego-vehicle yaw rate value is deducted from the measured relative azimuth rate value and then shall be added downstream.  Due to this, the signal is not strictly, a derivative of the corresponding angular coordinate.";
CM_ SG_ 640 VHL_3_LEFT_AZIMUTH_RATE "Horizontal relative azimuth angular velocity of the Left side of vehicle detected at the extreme Left of the cluster. It is calculated in the camera coordinates system. The ego-vehicle yaw rate value is deducted from the measured relative azimuth rate value and then shall be added downstream.  Due to this, the signal is not strictly, a derivative of the corresponding angular coordinate.";
CM_ SG_ 642 TRAFFIC_IS_DETECTED "Indicates if at least one vehicle object (oncoming, oncoming clearance, leading or side) is detected in front of the ego-vehicle.";
CM_ SG_ 642 RFL_1_BRIGHTNESS "The brightness of the reflector object.";
CM_ SG_ 642 RFL_2_BRIGHTNESS "The brightness of the reflector object.";
CM_ SG_ 642 RFL_3_BRIGHTNESS "The brightness of the reflector object.";
CM_ SG_ 642 RFL_1_TOP_ANGLE "Angle to top of the reflector object";
CM_ SG_ 642 RFL_2_TOP_ANGLE "Angle to top of the reflector object";
CM_ SG_ 642 RFL_3_TOP_ANGLE "Angle to top of the reflector object";
CM_ SG_ 642 RFL_1_BOTTOM_ANGLE "Angle to bottom of the reflector object";
CM_ SG_ 642 RFL_2_BOTTOM_ANGLE "Angle to bottom of the reflector object";
CM_ SG_ 642 RFL_3_BOTTOM_ANGLE "Angle to bottom of the reflector object";
CM_ SG_ 642 VHL_1_MIN_DISTANCE "Horizontal minimum distance to the closest vehicle detected in the cluster 1.";
CM_ SG_ 642 VHL_2_MIN_DISTANCE "Horizontal minimum distance to the closest vehicle detected in the cluster 1.";
CM_ SG_ 642 VHL_3_MIN_DISTANCE "Horizontal minimum distance to the closest vehicle detected in the cluster 1.";
CM_ SG_ 642 VHL_4_MIN_DISTANCE "Horizontal minimum distance to the closest vehicle detected in the cluster 1.";
CM_ SG_ 642 VHL_5_MIN_DISTANCE "Horizontal minimum distance to the closest vehicle detected in the cluster 1.";
CM_ SG_ 642 VHL_4_LEFT_AZIMUTH_RATE "Horizontal relative azimuth angular velocity of the Left side of vehicle detected at the extreme Left of the cluster. It is calculated in the camera coordinates system. The ego-vehicle yaw rate value is deducted from the measured relative azimuth rate value and then shall be added downstream.  Due to this, the signal is not strictly, a derivative of the corresponding angular coordinate.";
CM_ SG_ 642 VHL_5_LEFT_AZIMUTH_RATE "Horizontal relative azimuth angular velocity of the Left side of vehicle detected at the extreme Left of the cluster. It is calculated in the camera coordinates system. The ego-vehicle yaw rate value is deducted from the measured relative azimuth rate value and then shall be added downstream.  Due to this, the signal is not strictly, a derivative of the corresponding angular coordinate.";
CM_ SG_ 642 RFL_1_RIGHT_ANGLE "Angle to Right of the reflector object";
CM_ SG_ 642 RFL_2_RIGHT_ANGLE "Angle to Right of the reflector object";
CM_ SG_ 642 RFL_3_RIGHT_ANGLE "Angle to Right of the reflector object";
CM_ SG_ 642 RFL_1_LEFT_ANGLE "Angle to left of the reflector object";
CM_ SG_ 642 RFL_2_LEFT_ANGLE "Angle to left of the reflector object";
CM_ SG_ 642 RFL_3_LEFT_ANGLE "Angle to left of the reflector object";
CM_ SG_ 642 RFL_1_LEFT_AZIMUTH_RATE "Horizontal relative azimuth angular velocity of the left side of reflector object <n>. It is calculated in the camera coordinates system camera coordinates system. The ego-vehicle yaw rate value is deducted from the measured relative azimuth rate value and then shall be added downstream.  Due to this, the signal is not strictly, a derivative of the corresponding angular coordinate. ";
CM_ SG_ 642 RFL_2_LEFT_AZIMUTH_RATE "Horizontal relative azimuth angular velocity of the left side of reflector object <n>. It is calculated in the camera coordinates system camera coordinates system. The ego-vehicle yaw rate value is deducted from the measured relative azimuth rate value and then shall be added downstream.  Due to this, the signal is not strictly, a derivative of the corresponding angular coordinate. ";
CM_ SG_ 642 RFL_3_LEFT_AZIMUTH_RATE "Horizontal relative azimuth angular velocity of the left side of reflector object <n>. It is calculated in the camera coordinates system camera coordinates system. The ego-vehicle yaw rate value is deducted from the measured relative azimuth rate value and then shall be added downstream.  Due to this, the signal is not strictly, a derivative of the corresponding angular coordinate. ";
CM_ SG_ 642 RFL_1_RIGHT_AZIMUTH_RATE "Horizontal relative azimuth angular velocity of the right side of reflector object <X>. It is calculated in the camera coordinates system camera coordinates system. The ego-vehicle yaw rate value is deducted from the measured relative azimuth rate value and then shall be added downstream.  Due to this, the signal is not strictly, a derivative of the corresponding angular coordinate.";
CM_ SG_ 642 RFL_2_RIGHT_AZIMUTH_RATE "Horizontal relative azimuth angular velocity of the right side of reflector object <X>. It is calculated in the camera coordinates system camera coordinates system. The ego-vehicle yaw rate value is deducted from the measured relative azimuth rate value and then shall be added downstream.  Due to this, the signal is not strictly, a derivative of the corresponding angular coordinate.";
CM_ SG_ 642 RFL_3_RIGHT_AZIMUTH_RATE "Horizontal relative azimuth angular velocity of the right side of reflector object <X>. It is calculated in the camera coordinates system camera coordinates system. The ego-vehicle yaw rate value is deducted from the measured relative azimuth rate value and then shall be added downstream.  Due to this, the signal is not strictly, a derivative of the corresponding angular coordinate.";
CM_ SG_ 642 RFL_3_DISTANCE "Distance to reflector object";
CM_ SG_ 642 RFL_2_DISTANCE "Distance to reflector object";
CM_ SG_ 642 RFL_1_DISTANCE "Distance to reflector object";
CM_ SG_ 642 VHL_1_VDID "to define if the detection of the vehicle object <X> is taking into account the fusion between LSV (light rectangle) and 3DVD (3D bounding box detection) or Not. Description to be reviewed with ME";
CM_ SG_ 642 VHL_2_VDID "to define if the detection of the vehicle object <X> is taking into account the fusion between LSV (light rectangle) and 3DVD (3D bounding box detection) or Not. Description to be reviewed with ME";
CM_ SG_ 642 VHL_3_VDID "to define if the detection of the vehicle object <X> is taking into account the fusion between LSV (light rectangle) and 3DVD (3D bounding box detection) or Not. Description to be reviewed with ME";
CM_ SG_ 642 VHL_4_VDID "to define if the detection of the vehicle object <X> is taking into account the fusion between LSV (light rectangle) and 3DVD (3D bounding box detection) or Not. Description to be reviewed with ME";
CM_ SG_ 642 VHL_5_VDID "to define if the detection of the vehicle object <X> is taking into account the fusion between LSV (light rectangle) and 3DVD (3D bounding box detection) or Not. Description to be reviewed with ME";
CM_ SG_ 642 VHL_1_ID "Vehicle cluster object ID (based on light detection and object clustering). Updated each frame. Range is 0-255, the value 0 indicates that the field in unfilled.";
CM_ SG_ 642 VHL_2_ID "Vehicle cluster object ID (based on light detection and object clustering). Updated each frame. Range is 0-255, the value 0 indicates that the field in unfilled.";
CM_ SG_ 642 VHL_3_ID "Vehicle cluster object ID (based on light detection and object clustering). Updated each frame. Range is 0-255, the value 0 indicates that the field in unfilled.";
CM_ SG_ 642 VHL_4_ID "Vehicle cluster object ID (based on light detection and object clustering). Updated each frame. Range is 0-255, the value 0 indicates that the field in unfilled.";
CM_ SG_ 642 VHL_5_ID "Vehicle cluster object ID (based on light detection and object clustering). Updated each frame. Range is 0-255, the value 0 indicates that the field in unfilled.";
CM_ SG_ 642 RFL_1_ID "Id of the reflector object number <X>. Range is 0-255, the value 0 indicates that the field in unfilled.";
CM_ SG_ 642 RFL_2_ID "Id of the reflector object number <X>. Range is 0-255, the value 0 indicates that the field in unfilled.";
CM_ SG_ 642 RFL_3_ID "Id of the reflector object number <X>. Range is 0-255, the value 0 indicates that the field in unfilled.";
CM_ SG_ 645 ACC_FRONT_TARGET_DISTANCE "Distance to ACC Frontal  target (Ego Front bumper to Front Target rear bumper)";
CM_ SG_ 645 ACC_ACCEL_SETPOINT_REQ "ACC Acceleration setpoint requested by the vehicle";
CM_ SG_ 645 ACC_FRONT_TARGET_RELARIVE_ACCEL "Relative acceleration of the Frontal Target";
CM_ SG_ 645 ACC_FRONT_TARGET_RELARIVE_SPEED "Relative Speed of the frontal target";
CM_ SG_ 645 ACC_DESIRED_INTERVEHICLE_DIST "Desired Distance set point to ACC Frontal  target";
CM_ SG_ 645 ACC_FRONT_TARGET_CRITICITY "Criticality of the target";
CM_ SG_ 645 ACC_FRONT_TARGET_POSITION "Longitudinal position of Target object based on 64 positions scale";
CM_ SG_ 645 ACC_FRONT_TARGET_TYPE "Type of detected target object";
CM_ SG_ 645 E2E_CRC_LRCF_DATA_9 "Description : 
DATA_ID = 0x0113
From byte 1 to byte 32(PSA Convention) / DATA_ID = 0x0113
From byte 1 to byte 32 (PSA Convention)
 / 
";
CM_ SG_ 645 E2E_ALIVE_LRCF_DATA_9 " E2E Process Counter for FD14_HPC_DATA_7 frame";
CM_ SG_ 645 EGO_LANE_WIDTH "Ego Lane Width";
CM_ SG_ 645 EGO_LANE_NUMBER "Ego Estimated position in the road in the same direction of EGO";
CM_ SG_ 645 FRONT_EGO_LANE_LOWER_LIMIT "Definition of the Lane in front the ego vehicle : lower limit";
CM_ SG_ 645 FRONT_EGO_LANE_UPPER_LIMIT "Definition of the Lane in front the ego vehicle : Upper limit";
CM_ SG_ 645 EGO_LANE_QUALITY "Model Conformity of the Lane in front the ego vehicle";
CM_ SG_ 645 FRONT_EGO_LANE_A0_POLY_COEF "Definition of  the Lane in front the ego vehicle : a0 polynomial coefficient";
CM_ SG_ 645 FRONT_EGO_LANE_A1_POLY_COEF "Definition of the Lane in front the ego vehicle : a1 olynomial coefficient";
CM_ SG_ 645 FRONT_EGO_LANE_A2_POLY_COEF "Definition of the Lane in front the ego vehicle : a2 polynomial coefficient";
CM_ SG_ 645 FRONT_EGO_LANE_A3_POLY_COEF "Definition of the Lane in front the ego vehicle : a3 polynomial coefficient";
CM_ SG_ 282 E2E_ALIVE_ORC_DATA_1_11A " E2E Process Counter for FD14_ORC_DATA_1 frame";
CM_ SG_ 282 E2E_CRC_ORC_DATA_1_11A "Description : 
DATA_ID = 0x00D4
From byte 1 to byte 32(PSA Convention) / DATA_ID = 0x00D4
From byte 1 to byte 32 (PSA Convention)
 / 

Commentaires : 
Please refer to reference specification. / Please refer to reference specification.";
CM_ SG_ 282 YAW_RATE "Calculated Carbody Yaw velocity based on the IMU Raw value, with the static offset corrected in plant.";
CM_ SG_ 282 LAT_ACCELERATION "Calculated Carbody Lateral acceleration based on the IMU Raw value, with the static offset corrected in plant";
CM_ SG_ 282 LONG_ACCELERATION "Calculated Carbody Longitudinal acceleration based on the IMU Raw value, with the static offset corrected in plant";
CM_ SG_ 2654339201 EOL_LRCF "Indicates if the ECU requires configuration data at the assembly plant End Of Line";
CM_ SG_ 2654339201 CurrentCanNMState_FD15_LRCF "Indicates that CanNM state the ECU is currently executing";
CM_ SG_ 2654503041 NM_STATE "Status of the supervision task
";
CM_ SG_ 2654503041 CurrentCanNMState_FD15_LRCF "Indicates that CanNM state the ECU is currently executing";
CM_ SG_ 2654502924 NM_STATE "Status of the supervision task
";
CM_ SG_ 2654502924 CurrentCanNMState_FD15_ZCU_F "Indicates that CanNM state the ECU is currently executing";
CM_ SG_ 129 VERSION_DATA "Version Data";
CM_ SG_ 121 ECU_Code_ACK "ECU code of the defect sender";
CM_ SG_ 121 Rep_UCE "Acknowledgement of a request for read the defect event history";
CM_ SG_ 556 ACC_STATE_INFO_FOR_CHASSIS "FT0 state to control FT2's VMC Inactive : 0 Active : 1 ActiveBrakeOnly : 2 ActiveStandstill : 3";
CM_ SG_ 556 PACC_ACCEL_LONGI_REQUEST "PACC acceleration set point";
CM_ SG_ 556 PACC_BEVENT_IN_PROGRESS "PACC acceleration request flag";
CM_ SG_ 1546 DRIVER_DOOR_OPEN_STATUS "Used to indicate the status of driver door";
CM_ SG_ 1546 EXT_TEMP_FILTRED_DEG_C "The filtred temperature in degree Celsius";
CM_ SG_ 1546 HEADLAMP_WITH_WIPER_REQ "headlamps on with wipers feature request";
CM_ SG_ 1546 TRAILER_CONNECTION_STS "Indication of the connectivity of trailer";
CM_ SG_ 1546 PASSENGER_DOOR_OPEN_STATUS "Front passenger door's open status";
CM_ SG_ 1546 TURN_SIGNAL_STS "Turn signal mode, indicate which side(s) activated.";
CM_ SG_ 1546 DAY_NIGHT_STATUS "Day light brightness mode display";
CM_ SG_ 1546 FRT_WIPING_CONF "Front wiping status in case we have a rain situation without HRLS sensor";
CM_ SG_ 1546 DRIVING_MODE_POWERTRAIN_REQ "Specific propulsion mode selected
";
CM_ SG_ 1032 DRIVER_SEATBELT_BUCKLE_SECU_DATA "First row driver seatbelt switch status";
CM_ SG_ 1032 ROW1_P_SEATBELT_BUCKLE_SECU_DATA "First row driver seatbelt switch status";
CM_ SG_ 1032 TURN_INDICATOR_DRIVER_DMD "Description:
Demand for turn indicator activation(left or right) coming from the stalk";
CM_ SG_ 1032 VIN_INFORMATION "It represents the VIN Message Information";
CM_ SG_ 1289 BLINDSPOTDETECTION_DRIVERREQUEST "Specifies the status of Blind Spot Detection function activation request";
CM_ SG_ 1034 VEHICLE_IGNITION_STATUS "This flow is used to give information about ignition status of the vehicle. The signal can be also briefly called as CmdIgnSts.";
CM_ SG_ 1034 VEHICLE_MODE_CONFIGURATION "It represents the vehicle configuration mode";
CM_ SG_ 1034 E2E_CRC_ZCU_CL_GLOBAL_DATA_40A "Description : 
DATA_ID = 0x00D8
From byte 1 to byte 32(PSA Convention) / DATA_ID = 0x00D8
From byte 1 to byte 32 (PSA Convention)
 / 
";
CM_ SG_ 1034 E2E_ALIVE_ZCU_CL_GLOBAL_DATA_40A " E2E Process Counter for FD14_ZCU_CL_GLOBAL_DATA frame";
CM_ SG_ 1034 DAY_LIGHT_MODE_CMD "This Flow Represent the status of the day/night Mode";
CM_ SG_ 1034 BACK_LIGHT_INTENSITY_CMD "this flow represent the command of the backlighting intensity";
CM_ SG_ 1550 ESC_TCS_FAILSTATUS "It provides the request to turn the telltale on in case of failure of the ESC or TCS functions";
CM_ SG_ 1550 WHEEL_SPARE_SIZEDETECTION_STATE "It provides the small diameter wheel detection state mainly for spare wheel situation
";
CM_ SG_ 1550 E2E_CRC_ZCU_F_DATA_15 "Description : 
DATA_ID =0x0119
From byte 1 to byte 32(PSA Convention) / DATA_ID = 0x010C
From byte 1 to byte 32 (PSA Convention)
 / 

Commentaires : 
Please refer to reference specification. / Please refer to reference specification.";
CM_ SG_ 1550 E2E_ALIVE_ZCU_F_DATA_15 " E2E Process Counter for FD14_BSM_DATA_10 frame";
CM_ SG_ 270 ACCEL_PEDAL_PERCENT_PWT "Gas Pedal percentage representation acquired from the pedal sensor, based on voltage inputs.";
CM_ SG_ 270 PRND_ENGAGED_FOR_DISPLAY "Transmission Gear Engaged signal for the instrument cluster display";
CM_ SG_ 270 PRND_TARGET_STATE "Intended Gear that the transmission will shift to.";
CM_ SG_ 270 E2E_CRC_ZCU_F_DATA_9 "Description : 
DATA_ID = 0x00DB
From byte 1 to byte 32(PSA Convention) / DATA_ID = 0x00DB
From byte 1 to byte 32 (PSA Convention)
 / 
";
CM_ SG_ 270 E2E_ALIVE_ZCU_F_DATA_9 " E2E Process Counter for FD15_ZCU_F_DATA_9 frame";
CM_ SG_ 270 HANDWHEEL_STEERING_ANGLE_VALUE_S " Handwheel rotation angle applied by the drive.
Only for Steering By Wire";
CM_ SG_ 270 LXA_STEERING_STATE_S "state request from ESC to EPS for perform the yaw control by rack position control";
CM_ SG_ 270 STEERING_ASSIST_STATUS_S " functional state of the Steering system";
CM_ SG_ 270 STEERINGWHEEL_ANGLE_REL_FRT_VA_S "front relative steering wheel angle with no correction (raw)";
CM_ SG_ 270 STEERINGWHEEL_ROT_VELOCITY_FRT_S "front steering wheel velocity angle (Absolute value or Relative value corrected)";
CM_ SG_ 270 ACC_STATE_INFO_IN_POWERTRAIN "VMC EP regulation state feedback";
CM_ SG_ 270 STEERINGWHEEL_ANGLE_FRONT_VAL_S "front steering wheel angle (absolute value or Relative value corrected). Counterclockwise positive.";
CM_ SG_ 270 CRUISE_CONTROL_STATUS "Cruise control status powertrain feedback.";
CM_ SG_ 1035 PROPULSION_SYSTEM_ACTIVE "Propulsion system active status";
CM_ SG_ 1035 E2E_CRC_ZCU_F_GLOBAL_DATA "Description : 
DATA_ID = 0x00D9
From byte 1 to byte 32(PSA Convention) / DATA_ID = 0x00D9
From byte 1 to byte 32 (PSA Convention)
 / 
";
CM_ SG_ 1035 E2E_ALIVE_ZCU_F_GLOBAL_DATA_40B " E2E Process Counter for FDxx_ZCU_F_GLOBAL_DATA_40B frames";
CM_ SG_ 1035 TOTAL_ODOMETER "This flow represents the total mileage traveled by the vehicle.";
CM_ SG_ 1035 TRUSTED_TIME_YEAR " Year according to UTCTime clock time";
CM_ SG_ 1035 TRUSTED_TIME_MONTH "Month according to UTCTime clock time";
CM_ SG_ 1035 TRUSTED_TIME_DAY "Day according to UTCTime clock time";
CM_ SG_ 1035 TRUSTED_TIME_HOUR "Hour according to UTCTime clock time";
CM_ SG_ 1035 SHUTDOWN_NTW_FD_CAN14 "FD_CAN14 network shutdown from ZCU_F
";
CM_ SG_ 1035 SHUTDOWN_NTW_FD_CAN5 "FD_CAN5 network shutdown from ZCU_F
";

BA_DEF_ SG_ "Accuracy" STRING ;
BA_DEF_ SG_ "Event trans." ENUM "Yes","No";
BA_DEF_ SG_ "GenSigStartValue" INT 0 9223372036854775807;

BA_DEF_ SG_ "GenSigSendType" ENUM "cyclicAndSpontaneousWithDelay","cyclic","spontaneousWithDelay","N_A","";
BA_DEF_ BO_ "DiagRequest" ENUM "No","Yes";
BA_DEF_ BO_ "Period [ms]" INT 0 65535;
BA_DEF_ BO_ "Type" ENUM "P","P+E","E","-";
BA_DEF_ BO_ "DiagResponse" ENUM "No","Yes";
BA_DEF_ BO_ "NmMessage" ENUM "No","Yes";
BA_DEF_ BO_ "GenMsgSendType" ENUM "cyclic","cyclicAndSpontaneousWithDelay","spontaneousWithDelay","N_A";
BA_DEF_ BO_ "GenMsgTimeoutTime" INT 0 10000;
BA_DEF_ BO_ "GenMsgILSupport" ENUM "No","Yes";
BA_DEF_ BO_ "GenMsgStartDelayTime" INT 0 65535;
BA_DEF_ BO_ "GenMsgCycleTime" INT 0 65535;
BA_DEF_ BO_ "GenMsgDelayTime" INT 0 65535;
BA_DEF_ BO_ "DiagState" ENUM "No","Yes";
BA_DEF_ BO_ "VFrameFormat" ENUM "StandardCAN","ExtendedCAN","reserved","reserved","reserved","reserved","reserved","reserved","reserved","reserved","reserved","reserved","reserved","reserved","StandardCAN_FD","ExtendedCAN_FD";
BA_DEF_ BO_ "CANFD_BRS" ENUM "0","1";
BA_DEF_DEF_ "DiagRequest" "No";
BA_DEF_DEF_ "Period [ms]" 0;
BA_DEF_DEF_ "Type" "-";
BA_DEF_DEF_ "DiagResponse" "No";
BA_DEF_DEF_ "NmMessage" "No";
BA_DEF_DEF_ "GenMsgSendType" "N_A";
BA_DEF_DEF_ "GenMsgTimeoutTime" 0;
BA_DEF_DEF_ "GenMsgILSupport" "No";
BA_DEF_DEF_ "GenMsgStartDelayTime" 0;
BA_DEF_DEF_ "GenMsgCycleTime" 0;
BA_DEF_DEF_ "GenMsgDelayTime" 0;
BA_DEF_DEF_ "DiagState" "No";
BA_DEF_DEF_ "VFrameFormat" "StandardCAN_FD";
BA_DEF_DEF_ "CANFD_BRS" "0";
BA_DEF_DEF_ "Accuracy" "";
BA_DEF_DEF_ "Event trans." "No";
BA_DEF_DEF_ "GenSigStartValue" 0;

BA_DEF_DEF_ "GenSigSendType" "";
BA_ "Period [ms]" BO_ 1152 100;
BA_ "GenMsgSendType" BO_ 1152 0;
BA_ "GenMsgILSupport" BO_ 1152 1;
BA_ "GenMsgStartDelayTime" BO_ 1152 50;
BA_ "GenMsgCycleTime" BO_ 1152 100;
BA_ "CANFD_BRS" BO_ 1152 1;
BA_ "Period [ms]" BO_ 897 50;
BA_ "GenMsgSendType" BO_ 897 0;
BA_ "GenMsgILSupport" BO_ 897 1;
BA_ "GenMsgStartDelayTime" BO_ 897 10;
BA_ "GenMsgCycleTime" BO_ 897 50;
BA_ "CANFD_BRS" BO_ 897 1;
BA_ "Period [ms]" BO_ 640 20;
BA_ "GenMsgSendType" BO_ 640 0;
BA_ "GenMsgILSupport" BO_ 640 1;
BA_ "GenMsgCycleTime" BO_ 640 20;
BA_ "CANFD_BRS" BO_ 640 1;
BA_ "Period [ms]" BO_ 642 20;
BA_ "GenMsgSendType" BO_ 642 0;
BA_ "GenMsgILSupport" BO_ 642 1;
BA_ "GenMsgStartDelayTime" BO_ 642 10;
BA_ "GenMsgCycleTime" BO_ 642 20;
BA_ "CANFD_BRS" BO_ 642 1;
BA_ "Period [ms]" BO_ 645 20;
BA_ "GenMsgSendType" BO_ 645 0;
BA_ "GenMsgILSupport" BO_ 645 1;
BA_ "GenMsgStartDelayTime" BO_ 645 10;
BA_ "GenMsgCycleTime" BO_ 645 20;
BA_ "CANFD_BRS" BO_ 645 1;
BA_ "NmMessage" BO_ 2654486657 1;
BA_ "GenMsgSendType" BO_ 2654486657 2;
BA_ "VFrameFormat" BO_ 2654486657 15;
BA_ "CANFD_BRS" BO_ 2654486657 1;
BA_ "Period [ms]" BO_ 282 10;
BA_ "GenMsgSendType" BO_ 282 0;
BA_ "GenMsgILSupport" BO_ 282 1;
BA_ "GenMsgCycleTime" BO_ 282 10;
BA_ "CANFD_BRS" BO_ 282 1;
BA_ "Period [ms]" BO_ 2654339201 1000;
BA_ "GenMsgSendType" BO_ 2654339201 0;
BA_ "GenMsgILSupport" BO_ 2654339201 1;
BA_ "GenMsgStartDelayTime" BO_ 2654339201 500;
BA_ "GenMsgCycleTime" BO_ 2654339201 1000;
BA_ "VFrameFormat" BO_ 2654339201 15;
BA_ "CANFD_BRS" BO_ 2654339201 1;
BA_ "Period [ms]" BO_ 2654503041 100;
BA_ "GenMsgSendType" BO_ 2654503041 0;
BA_ "GenMsgILSupport" BO_ 2654503041 1;
BA_ "GenMsgStartDelayTime" BO_ 2654503041 20;
BA_ "GenMsgCycleTime" BO_ 2654503041 100;
BA_ "VFrameFormat" BO_ 2654503041 15;
BA_ "CANFD_BRS" BO_ 2654503041 1;
BA_ "Period [ms]" BO_ 2654502924 100;
BA_ "GenMsgSendType" BO_ 2654502924 0;
BA_ "GenMsgILSupport" BO_ 2654502924 1;
BA_ "GenMsgStartDelayTime" BO_ 2654502924 210;
BA_ "GenMsgCycleTime" BO_ 2654502924 100;
BA_ "VFrameFormat" BO_ 2654502924 15;
BA_ "CANFD_BRS" BO_ 2654502924 1;
BA_ "GenMsgSendType" BO_ 129 2;
BA_ "GenMsgILSupport" BO_ 129 1;
BA_ "GenMsgDelayTime" BO_ 129 10;
BA_ "CANFD_BRS" BO_ 129 1;
BA_ "GenMsgSendType" BO_ 121 2;
BA_ "GenMsgILSupport" BO_ 121 1;
BA_ "GenMsgDelayTime" BO_ 121 10;
BA_ "CANFD_BRS" BO_ 121 1;
BA_ "Period [ms]" BO_ 556 20;
BA_ "GenMsgSendType" BO_ 556 0;
BA_ "GenMsgILSupport" BO_ 556 1;
BA_ "GenMsgCycleTime" BO_ 556 20;
BA_ "CANFD_BRS" BO_ 556 1;
BA_ "Period [ms]" BO_ 1546 500;
BA_ "GenMsgSendType" BO_ 1546 1;
BA_ "GenMsgILSupport" BO_ 1546 1;
BA_ "GenMsgStartDelayTime" BO_ 1546 2810;
BA_ "GenMsgCycleTime" BO_ 1546 500;
BA_ "GenMsgDelayTime" BO_ 1546 10;
BA_ "CANFD_BRS" BO_ 1546 1;
BA_ "Period [ms]" BO_ 1032 100;
BA_ "GenMsgSendType" BO_ 1032 1;
BA_ "GenMsgILSupport" BO_ 1032 1;
BA_ "GenMsgStartDelayTime" BO_ 1032 140;
BA_ "GenMsgCycleTime" BO_ 1032 100;
BA_ "GenMsgDelayTime" BO_ 1032 10;
BA_ "CANFD_BRS" BO_ 1032 1;
BA_ "Period [ms]" BO_ 1289 200;
BA_ "GenMsgSendType" BO_ 1289 1;
BA_ "GenMsgILSupport" BO_ 1289 1;
BA_ "GenMsgStartDelayTime" BO_ 1289 2050;
BA_ "GenMsgCycleTime" BO_ 1289 200;
BA_ "GenMsgDelayTime" BO_ 1289 10;
BA_ "CANFD_BRS" BO_ 1289 1;
BA_ "Period [ms]" BO_ 1034 100;
BA_ "GenMsgSendType" BO_ 1034 1;
BA_ "GenMsgILSupport" BO_ 1034 1;
BA_ "GenMsgStartDelayTime" BO_ 1034 150;
BA_ "GenMsgCycleTime" BO_ 1034 100;
BA_ "GenMsgDelayTime" BO_ 1034 10;
BA_ "CANFD_BRS" BO_ 1034 1;
BA_ "Period [ms]" BO_ 1550 500;
BA_ "GenMsgSendType" BO_ 1550 1;
BA_ "GenMsgILSupport" BO_ 1550 1;
BA_ "GenMsgStartDelayTime" BO_ 1550 2940;
BA_ "GenMsgCycleTime" BO_ 1550 500;
BA_ "GenMsgDelayTime" BO_ 1550 10;
BA_ "CANFD_BRS" BO_ 1550 1;
BA_ "Period [ms]" BO_ 1055 50;
BA_ "GenMsgSendType" BO_ 1055 1;
BA_ "GenMsgILSupport" BO_ 1055 1;
BA_ "GenMsgStartDelayTime" BO_ 1055 170;
BA_ "GenMsgCycleTime" BO_ 1055 50;
BA_ "GenMsgDelayTime" BO_ 1055 10;
BA_ "CANFD_BRS" BO_ 1055 1;
BA_ "Period [ms]" BO_ 270 10;
BA_ "GenMsgSendType" BO_ 270 0;
BA_ "GenMsgILSupport" BO_ 270 1;
BA_ "GenMsgCycleTime" BO_ 270 10;
BA_ "CANFD_BRS" BO_ 270 1;
BA_ "Period [ms]" BO_ 1035 100;
BA_ "GenMsgSendType" BO_ 1035 1;
BA_ "GenMsgILSupport" BO_ 1035 1;
BA_ "GenMsgStartDelayTime" BO_ 1035 160;
BA_ "GenMsgCycleTime" BO_ 1035 100;
BA_ "GenMsgDelayTime" BO_ 1035 10;
BA_ "CANFD_BRS" BO_ 1035 1;
BA_ "GenSigStartValue" SG_ 1152 SMARTE_COAST_FR_TAR_DIST 32640;

BA_ "GenSigSendType" SG_ 1152 SMARTE_COAST_FR_TAR_DIST 1;
BA_ "GenSigStartValue" SG_ 1152 SMARTE_COAST_FR_TAR_CONFI 1;

BA_ "GenSigSendType" SG_ 1152 SMARTE_COAST_FR_TAR_CONFI 1;
BA_ "GenSigStartValue" SG_ 1152 SMARTE_COAST_FR_REL_SPEED 32768;

BA_ "GenSigSendType" SG_ 1152 SMARTE_COAST_FR_REL_SPEED 1;
BA_ "GenSigStartValue" SG_ 897 FRONT_CAMERA_RIGHTLINE_CURV_DERI 65535;

BA_ "GenSigSendType" SG_ 897 FRONT_CAMERA_RIGHTLINE_CURV_DERI 1;
BA_ "GenSigStartValue" SG_ 897 FRONT_CAMERA_LEFTLINE_CURV_DERI 65535;

BA_ "GenSigSendType" SG_ 897 FRONT_CAMERA_LEFTLINE_CURV_DERI 1;
BA_ "GenSigStartValue" SG_ 897 FRONT_CAMERA_LEFTLINE_DISTANCE 2047;

BA_ "GenSigSendType" SG_ 897 FRONT_CAMERA_LEFTLINE_DISTANCE 1;
BA_ "GenSigStartValue" SG_ 897 FRONT_CAMERA_RIGHTLINE_DISTANCE 2047;

BA_ "GenSigSendType" SG_ 897 FRONT_CAMERA_RIGHTLINE_DISTANCE 1;
BA_ "GenSigStartValue" SG_ 897 FRONT_CAMERA_LEFTLINE_CURVATURE 65535;

BA_ "GenSigSendType" SG_ 897 FRONT_CAMERA_LEFTLINE_CURVATURE 1;
BA_ "GenSigStartValue" SG_ 897 FRONT_CAMERA_RIGHTLINE_CURVATURE 65535;

BA_ "GenSigSendType" SG_ 897 FRONT_CAMERA_RIGHTLINE_CURVATURE 1;

BA_ "GenSigSendType" SG_ 897 FRONT_CAMERA_RIGHTLINE_DETECTION 1;

BA_ "GenSigSendType" SG_ 897 FRONT_CAMERA_LEFTLINE_DETECTION 1;
BA_ "GenSigStartValue" SG_ 897 FRONT_CAMERA_LANE_STATUS 3;

BA_ "GenSigSendType" SG_ 897 FRONT_CAMERA_LANE_STATUS 1;
BA_ "GenSigStartValue" SG_ 897 GFHB_CAMERA_STATUS 3;

BA_ "GenSigSendType" SG_ 897 GFHB_CAMERA_STATUS 1;

BA_ "GenSigSendType" SG_ 897 FRONT_CAM_RIGHT_LINE_TYPE 1;

BA_ "GenSigSendType" SG_ 897 FRONT_CAM_LEFT_LINE_TYPE 1;

BA_ "GenSigSendType" SG_ 897 FRONT_CAM_RIGHT_LINE_MARK_QLTY 1;

BA_ "GenSigSendType" SG_ 897 FRONT_CAM_LEFT_LINE_MARK_QLTY 1;
BA_ "GenSigStartValue" SG_ 897 FRONT_CAM_LEFT_LINE_HEADING_ANG 4094;

BA_ "GenSigSendType" SG_ 897 FRONT_CAM_LEFT_LINE_HEADING_ANG 1;
BA_ "GenSigStartValue" SG_ 897 FRONT_CAM_RIGHT_LINE_HEADING_ANG 4094;

BA_ "GenSigSendType" SG_ 897 FRONT_CAM_RIGHT_LINE_HEADING_ANG 1;

BA_ "GenSigSendType" SG_ 897 FRONT_CAM_LEFT_LINE_VIEW_RNG_ST 1;

BA_ "GenSigSendType" SG_ 897 FRONT_CAM_RIGHT_LINE_VIEW_RNG_ST 1;

BA_ "GenSigSendType" SG_ 897 FRONT_CAM_LEFT_LINE_VIEW_RNG_EN 1;

BA_ "GenSigSendType" SG_ 897 FRONT_CAM_RIGHT_LINE_VIEW_RNG_EN 1;

BA_ "GenSigSendType" SG_ 897 FRONT_CAM_NEXT_LEFT_LINE_TYPE 1;

BA_ "GenSigSendType" SG_ 897 FRONT_CAM_NEXT_RIGHT_LINE_TYPE 1;
BA_ "GenSigStartValue" SG_ 897 FRONTCAM_NEXTRIGHTLINE_CURV_DERI 65535;

BA_ "GenSigSendType" SG_ 897 FRONTCAM_NEXTRIGHTLINE_CURV_DERI 1;
BA_ "GenSigStartValue" SG_ 897 FRONTCAM_NEXTLEFTLINE_CURV_DERI 65535;

BA_ "GenSigSendType" SG_ 897 FRONTCAM_NEXTLEFTLINE_CURV_DERI 1;

BA_ "GenSigSendType" SG_ 897 FRONTCAM_NEXT_LEFTLINE_MARK_QLTY 1;

BA_ "GenSigSendType" SG_ 897 FRONTCAM_NEXTRIGHTLINE_MARKQLTY 1;

BA_ "GenSigSendType" SG_ 897 FRONT_CAM_RIGHT_LANE_DIRECTION 1;

BA_ "GenSigSendType" SG_ 897 FRONT_CAM_LEFT_LANE_DIRECTION 1;
BA_ "GenSigStartValue" SG_ 897 FRONTCAM_NEXT_LEFTLINE_LAT_DIST 63;

BA_ "GenSigSendType" SG_ 897 FRONTCAM_NEXT_LEFTLINE_LAT_DIST 1;
BA_ "GenSigStartValue" SG_ 897 FRONTCAM_NEXT_RIGHTLINE_LAT_DIST 63;

BA_ "GenSigSendType" SG_ 897 FRONTCAM_NEXT_RIGHTLINE_LAT_DIST 1;
BA_ "GenSigStartValue" SG_ 897 FRONTCAM_LEFTLINE_LAT_DIST 63;

BA_ "GenSigSendType" SG_ 897 FRONTCAM_LEFTLINE_LAT_DIST 1;
BA_ "GenSigStartValue" SG_ 897 FRONTCAM_RIGHTLINE_LAT_DIST 63;

BA_ "GenSigSendType" SG_ 897 FRONTCAM_RIGHTLINE_LAT_DIST 1;
BA_ "GenSigStartValue" SG_ 897 FRONTCAM_NEXTRIGHTLINE_CURVESTM 65535;

BA_ "GenSigSendType" SG_ 897 FRONTCAM_NEXTRIGHTLINE_CURVESTM 1;
BA_ "GenSigStartValue" SG_ 897 FRONTCAM_NEXTLEFTLINE_CURVESTIM 65535;

BA_ "GenSigSendType" SG_ 897 FRONTCAM_NEXTLEFTLINE_CURVESTIM 1;
BA_ "GenSigStartValue" SG_ 897 FRONTCAM_NEXTLEFTLINE_HEAD_ANG 4095;

BA_ "GenSigSendType" SG_ 897 FRONTCAM_NEXTLEFTLINE_HEAD_ANG 1;
BA_ "GenSigStartValue" SG_ 897 FRONTCAM_NEXTRIGHTLINE_HEAD_ANG 4095;

BA_ "GenSigSendType" SG_ 897 FRONTCAM_NEXTRIGHTLINE_HEAD_ANG 1;

BA_ "GenSigSendType" SG_ 897 FRONTCAM_NXTLEFTLINE_VIEW_RNG_ST 1;

BA_ "GenSigSendType" SG_ 897 FRONTCAM_NXTRIGHTLINE_VIEWRNG_ST 1;

BA_ "GenSigSendType" SG_ 897 FRONTCAM_NXTLEFTLINE_VIEW_RNG_EN 1;

BA_ "GenSigSendType" SG_ 897 FRONTCAM_NXTRIGHTLINE_VIEWRNG_EN 1;

BA_ "GenSigSendType" SG_ 897 FRONTCAM_NXTLEFTLINE_ROAD_EDGE 1;

BA_ "GenSigSendType" SG_ 897 FRONTCAM_NXTRIGHTLINE_ROAD_EDGE 1;

BA_ "GenSigSendType" SG_ 897 FRONTCAM_LEFTLINE_ROAD_EDGE 1;

BA_ "GenSigSendType" SG_ 897 FRONTCAM_RIGHTLINE_ROAD_EDGE 1;

BA_ "GenSigSendType" SG_ 897 FRONTCAM_LEFTLANE_DETECTION 1;

BA_ "GenSigSendType" SG_ 897 FRONTCAM_RIGHTLANE_DETECTION 1;

BA_ "GenSigSendType" SG_ 897 FRONTCAM_RIGHTHIGHWAY_EXITCONFID 1;

BA_ "GenSigSendType" SG_ 897 FRONTCAM_LEFT_HIGHWAY_EXITCONFID 1;

BA_ "GenSigSendType" SG_ 897 FRONTCAM_LEFT_HIGHWAY_EXIT 1;

BA_ "GenSigSendType" SG_ 897 FRONTCAM_NXT_LEFTLINE_COLOR 1;

BA_ "GenSigSendType" SG_ 897 FRONTCAM_NXT_RIGHTTLINE_COLOR 1;

BA_ "GenSigSendType" SG_ 897 FRONTCAM_LEFTLINE_COLOR 1;

BA_ "GenSigSendType" SG_ 897 FRONTCAM_RIGHTTLINE_COLOR 1;
BA_ "GenSigStartValue" SG_ 897 FRONTCAM_NXTLEFTLINE_DIST_ACTUAL 2047;

BA_ "GenSigSendType" SG_ 897 FRONTCAM_NXTLEFTLINE_DIST_ACTUAL 1;
BA_ "GenSigStartValue" SG_ 897 FRONTCAM_NXTRIGHTLINE_DISTACTUAL 2047;

BA_ "GenSigSendType" SG_ 897 FRONTCAM_NXTRIGHTLINE_DISTACTUAL 1;

BA_ "GenSigSendType" SG_ 897 FRONTCAM_NXT_LEFTLINE_DETECT_STS 1;

BA_ "GenSigSendType" SG_ 897 FRONTCAM_NXTRIGHTLINE_DETECT_STS 1;

BA_ "GenSigSendType" SG_ 897 FRONTCAM_LANE_CROSSING 1;

BA_ "GenSigSendType" SG_ 897 FRONTCAM_EGO_OBJ_CIPV 1;

BA_ "GenSigSendType" SG_ 897 FRONTCAM_EGO2_OBJ_CIPV 1;

BA_ "GenSigSendType" SG_ 897 FRONTCAM_L1_OBJ_CIPV 1;

BA_ "GenSigSendType" SG_ 897 FRONTCAM_L2_OBJ_CIPV 1;

BA_ "GenSigSendType" SG_ 897 FRONTCAM_L3_OBJ_CIPV 1;

BA_ "GenSigSendType" SG_ 897 FRONTCAM_R1_OBJ_CIPV 1;

BA_ "GenSigSendType" SG_ 897 FRONTCAM_R2_OBJ_CIPV 1;

BA_ "GenSigSendType" SG_ 897 FRONTCAM_R3_OBJ_CIPV 1;
BA_ "GenSigStartValue" SG_ 897 FRONTCAM_EGO_OBJ_LONGI_DISTANCE 255;

BA_ "GenSigSendType" SG_ 897 FRONTCAM_EGO_OBJ_LONGI_DISTANCE 1;
BA_ "GenSigStartValue" SG_ 897 FRONTCAM_EGO2_OBJ_LONGI_DISTANCE 255;

BA_ "GenSigSendType" SG_ 897 FRONTCAM_EGO2_OBJ_LONGI_DISTANCE 1;
BA_ "GenSigStartValue" SG_ 897 FRONTCAM_L1_OBJ_LONGI_DISTANCE 255;

BA_ "GenSigSendType" SG_ 897 FRONTCAM_L1_OBJ_LONGI_DISTANCE 1;
BA_ "GenSigStartValue" SG_ 897 FRONTCAM_L2_OBJ_LONGI_DISTANCE 255;

BA_ "GenSigSendType" SG_ 897 FRONTCAM_L2_OBJ_LONGI_DISTANCE 1;
BA_ "GenSigStartValue" SG_ 897 FRONTCAM_L3_OBJ_LONGI_DISTANCE 255;

BA_ "GenSigSendType" SG_ 897 FRONTCAM_L3_OBJ_LONGI_DISTANCE 1;
BA_ "GenSigStartValue" SG_ 897 FRONTCAM_R1_OBJ_LONGI_DISTANCE 255;

BA_ "GenSigSendType" SG_ 897 FRONTCAM_R1_OBJ_LONGI_DISTANCE 1;
BA_ "GenSigStartValue" SG_ 897 FRONTCAM_R2_OBJ_LONGI_DISTANCE 255;

BA_ "GenSigSendType" SG_ 897 FRONTCAM_R2_OBJ_LONGI_DISTANCE 1;
BA_ "GenSigStartValue" SG_ 897 FRONTCAM_R3_OBJ_LONGI_DISTANCE 255;

BA_ "GenSigSendType" SG_ 897 FRONTCAM_R3_OBJ_LONGI_DISTANCE 1;
BA_ "GenSigStartValue" SG_ 897 FRONTCAM_EGO_OBJ_LAT_REL_SPD 127;

BA_ "GenSigSendType" SG_ 897 FRONTCAM_EGO_OBJ_LAT_REL_SPD 1;
BA_ "GenSigStartValue" SG_ 897 FRONTCAM_EGO2_OBJ_LAT_REL_SPD 127;

BA_ "GenSigSendType" SG_ 897 FRONTCAM_EGO2_OBJ_LAT_REL_SPD 1;
BA_ "GenSigStartValue" SG_ 897 FRONTCAM_L1_OBJ_LAT_REL_SPD 127;

BA_ "GenSigSendType" SG_ 897 FRONTCAM_L1_OBJ_LAT_REL_SPD 1;
BA_ "GenSigStartValue" SG_ 640 VHL_1_CL_SUB_TYPE 7;

BA_ "GenSigSendType" SG_ 640 VHL_1_CL_SUB_TYPE 1;
BA_ "GenSigStartValue" SG_ 640 VHL_4_CL_SUB_TYPE 7;

BA_ "GenSigSendType" SG_ 640 VHL_4_CL_SUB_TYPE 1;
BA_ "GenSigStartValue" SG_ 640 VHL_5_CL_SUB_TYPE 7;

BA_ "GenSigSendType" SG_ 640 VHL_5_CL_SUB_TYPE 1;
BA_ "GenSigStartValue" SG_ 640 VHL_2_CL_SUB_TYPE 7;

BA_ "GenSigSendType" SG_ 640 VHL_2_CL_SUB_TYPE 1;
BA_ "GenSigStartValue" SG_ 640 VHL_3_CL_SUB_TYPE 7;

BA_ "GenSigSendType" SG_ 640 VHL_3_CL_SUB_TYPE 1;
BA_ "GenSigStartValue" SG_ 640 VHL_1_TYPE 6;

BA_ "GenSigSendType" SG_ 640 VHL_1_TYPE 1;
BA_ "GenSigStartValue" SG_ 640 VHL_2_TYPE 6;

BA_ "GenSigSendType" SG_ 640 VHL_2_TYPE 1;
BA_ "GenSigStartValue" SG_ 640 VHL_3_TYPE 6;

BA_ "GenSigSendType" SG_ 640 VHL_3_TYPE 1;
BA_ "GenSigStartValue" SG_ 640 VHL_4_TYPE 6;

BA_ "GenSigSendType" SG_ 640 VHL_4_TYPE 1;
BA_ "GenSigStartValue" SG_ 640 VHL_5_TYPE 6;

BA_ "GenSigSendType" SG_ 640 VHL_5_TYPE 1;
BA_ "GenSigStartValue" SG_ 640 VHL_3_LEFT_ANGLE 16383;

BA_ "GenSigSendType" SG_ 640 VHL_3_LEFT_ANGLE 1;
BA_ "GenSigStartValue" SG_ 640 VHL_1_LEFT_ANGLE 16383;

BA_ "GenSigSendType" SG_ 640 VHL_1_LEFT_ANGLE 1;
BA_ "GenSigStartValue" SG_ 640 VHL_2_LEFT_ANGLE 16383;

BA_ "GenSigSendType" SG_ 640 VHL_2_LEFT_ANGLE 1;
BA_ "GenSigStartValue" SG_ 640 VHL_4_LEFT_ANGLE 16383;

BA_ "GenSigSendType" SG_ 640 VHL_4_LEFT_ANGLE 1;
BA_ "GenSigStartValue" SG_ 640 VHL_5_LEFT_ANGLE 16383;

BA_ "GenSigSendType" SG_ 640 VHL_5_LEFT_ANGLE 1;
BA_ "GenSigStartValue" SG_ 640 VHL_1_BOTTOM_ANGLE 16383;

BA_ "GenSigSendType" SG_ 640 VHL_1_BOTTOM_ANGLE 1;
BA_ "GenSigStartValue" SG_ 640 VHL_2_BOTTOM_ANGLE 16383;

BA_ "GenSigSendType" SG_ 640 VHL_2_BOTTOM_ANGLE 1;
BA_ "GenSigStartValue" SG_ 640 VHL_3_BOTTOM_ANGLE 16383;

BA_ "GenSigSendType" SG_ 640 VHL_3_BOTTOM_ANGLE 1;
BA_ "GenSigStartValue" SG_ 640 VHL_4_BOTTOM_ANGLE 16383;

BA_ "GenSigSendType" SG_ 640 VHL_4_BOTTOM_ANGLE 1;
BA_ "GenSigStartValue" SG_ 640 VHL_5_BOTTOM_ANGLE 16383;

BA_ "GenSigSendType" SG_ 640 VHL_5_BOTTOM_ANGLE 1;
BA_ "GenSigStartValue" SG_ 640 VHL_1_RIGHT_ANGLE 16383;

BA_ "GenSigSendType" SG_ 640 VHL_1_RIGHT_ANGLE 1;
BA_ "GenSigStartValue" SG_ 640 VHL_2_RIGHT_ANGLE 16383;

BA_ "GenSigSendType" SG_ 640 VHL_2_RIGHT_ANGLE 1;
BA_ "GenSigStartValue" SG_ 640 VHL_3_RIGHT_ANGLE 16383;

BA_ "GenSigSendType" SG_ 640 VHL_3_RIGHT_ANGLE 1;
BA_ "GenSigStartValue" SG_ 640 VHL_4_RIGHT_ANGLE 16383;

BA_ "GenSigSendType" SG_ 640 VHL_4_RIGHT_ANGLE 1;
BA_ "GenSigStartValue" SG_ 640 VHL_5_RIGHT_ANGLE 16383;

BA_ "GenSigSendType" SG_ 640 VHL_5_RIGHT_ANGLE 1;
BA_ "GenSigStartValue" SG_ 640 VHL_1_LEFT_DISTANCE 1023;

BA_ "GenSigSendType" SG_ 640 VHL_1_LEFT_DISTANCE 1;
BA_ "GenSigStartValue" SG_ 640 VHL_2_LEFT_DISTANCE 1023;

BA_ "GenSigSendType" SG_ 640 VHL_2_LEFT_DISTANCE 1;
BA_ "GenSigStartValue" SG_ 640 VHL_3_LEFT_DISTANCE 1023;

BA_ "GenSigSendType" SG_ 640 VHL_3_LEFT_DISTANCE 1;
BA_ "GenSigStartValue" SG_ 640 VHL_4_LEFT_DISTANCE 1023;

BA_ "GenSigSendType" SG_ 640 VHL_4_LEFT_DISTANCE 1;
BA_ "GenSigStartValue" SG_ 640 VHL_5_LEFT_DISTANCE 1023;

BA_ "GenSigSendType" SG_ 640 VHL_5_LEFT_DISTANCE 1;
BA_ "GenSigStartValue" SG_ 640 VHL_1_RIGHT_DISTANCE 1023;

BA_ "GenSigSendType" SG_ 640 VHL_1_RIGHT_DISTANCE 1;
BA_ "GenSigStartValue" SG_ 640 VHL_2_RIGHT_DISTANCE 1023;

BA_ "GenSigSendType" SG_ 640 VHL_2_RIGHT_DISTANCE 1;
BA_ "GenSigStartValue" SG_ 640 VHL_3_RIGHT_DISTANCE 1023;

BA_ "GenSigSendType" SG_ 640 VHL_3_RIGHT_DISTANCE 1;
BA_ "GenSigStartValue" SG_ 640 VHL_4_RIGHT_DISTANCE 1023;

BA_ "GenSigSendType" SG_ 640 VHL_4_RIGHT_DISTANCE 1;
BA_ "GenSigStartValue" SG_ 640 VHL_5_RIGHT_DISTANCE 1023;

BA_ "GenSigSendType" SG_ 640 VHL_5_RIGHT_DISTANCE 1;
BA_ "GenSigStartValue" SG_ 640 VHL_1_RIGHT_AZIMUTH_RATE 4095;

BA_ "GenSigSendType" SG_ 640 VHL_1_RIGHT_AZIMUTH_RATE 1;
BA_ "GenSigStartValue" SG_ 640 VHL_2_RIGHT_AZIMUTH_RATE 4095;

BA_ "GenSigSendType" SG_ 640 VHL_2_RIGHT_AZIMUTH_RATE 1;
BA_ "GenSigStartValue" SG_ 640 VHL_3_RIGHT_AZIMUTH_RATE 4095;

BA_ "GenSigSendType" SG_ 640 VHL_3_RIGHT_AZIMUTH_RATE 1;
BA_ "GenSigStartValue" SG_ 640 VHL_4_RIGHT_AZIMUTH_RATE 4095;

BA_ "GenSigSendType" SG_ 640 VHL_4_RIGHT_AZIMUTH_RATE 1;
BA_ "GenSigStartValue" SG_ 640 VHL_5_RIGHT_AZIMUTH_RATE 4095;

BA_ "GenSigSendType" SG_ 640 VHL_5_RIGHT_AZIMUTH_RATE 1;
BA_ "GenSigStartValue" SG_ 640 VHL_1_LEFT_AZIMUTH_RATE 4095;

BA_ "GenSigSendType" SG_ 640 VHL_1_LEFT_AZIMUTH_RATE 1;
BA_ "GenSigStartValue" SG_ 640 VHL_2_LEFT_AZIMUTH_RATE 4095;

BA_ "GenSigSendType" SG_ 640 VHL_2_LEFT_AZIMUTH_RATE 1;
BA_ "GenSigStartValue" SG_ 640 VHL_3_LEFT_AZIMUTH_RATE 4095;

BA_ "GenSigSendType" SG_ 640 VHL_3_LEFT_AZIMUTH_RATE 1;
BA_ "GenSigStartValue" SG_ 642 TRAFFIC_IS_DETECTED 3;

BA_ "GenSigSendType" SG_ 642 TRAFFIC_IS_DETECTED 1;
BA_ "GenSigStartValue" SG_ 642 RFL_1_BRIGHTNESS 127;

BA_ "GenSigSendType" SG_ 642 RFL_1_BRIGHTNESS 1;
BA_ "GenSigStartValue" SG_ 642 RFL_2_BRIGHTNESS 127;

BA_ "GenSigSendType" SG_ 642 RFL_2_BRIGHTNESS 1;
BA_ "GenSigStartValue" SG_ 642 RFL_3_BRIGHTNESS 127;

BA_ "GenSigSendType" SG_ 642 RFL_3_BRIGHTNESS 1;
BA_ "GenSigStartValue" SG_ 642 RFL_1_TOP_ANGLE 2047;

BA_ "GenSigSendType" SG_ 642 RFL_1_TOP_ANGLE 1;
BA_ "GenSigStartValue" SG_ 642 RFL_2_TOP_ANGLE 2047;

BA_ "GenSigSendType" SG_ 642 RFL_2_TOP_ANGLE 1;
BA_ "GenSigStartValue" SG_ 642 RFL_3_TOP_ANGLE 2047;

BA_ "GenSigSendType" SG_ 642 RFL_3_TOP_ANGLE 1;
BA_ "GenSigStartValue" SG_ 642 RFL_1_BOTTOM_ANGLE 2047;

BA_ "GenSigSendType" SG_ 642 RFL_1_BOTTOM_ANGLE 1;
BA_ "GenSigStartValue" SG_ 642 RFL_2_BOTTOM_ANGLE 2047;

BA_ "GenSigSendType" SG_ 642 RFL_2_BOTTOM_ANGLE 1;
BA_ "GenSigStartValue" SG_ 642 RFL_3_BOTTOM_ANGLE 2047;

BA_ "GenSigSendType" SG_ 642 RFL_3_BOTTOM_ANGLE 1;
BA_ "GenSigStartValue" SG_ 642 VHL_1_MIN_DISTANCE 1023;

BA_ "GenSigSendType" SG_ 642 VHL_1_MIN_DISTANCE 1;
BA_ "GenSigStartValue" SG_ 642 VHL_2_MIN_DISTANCE 1023;

BA_ "GenSigSendType" SG_ 642 VHL_2_MIN_DISTANCE 1;
BA_ "GenSigStartValue" SG_ 642 VHL_3_MIN_DISTANCE 1023;

BA_ "GenSigSendType" SG_ 642 VHL_3_MIN_DISTANCE 1;
BA_ "GenSigStartValue" SG_ 642 VHL_4_MIN_DISTANCE 1023;

BA_ "GenSigSendType" SG_ 642 VHL_4_MIN_DISTANCE 1;
BA_ "GenSigStartValue" SG_ 642 VHL_5_MIN_DISTANCE 1023;

BA_ "GenSigSendType" SG_ 642 VHL_5_MIN_DISTANCE 1;
BA_ "GenSigStartValue" SG_ 642 VHL_4_LEFT_AZIMUTH_RATE 4095;

BA_ "GenSigSendType" SG_ 642 VHL_4_LEFT_AZIMUTH_RATE 1;
BA_ "GenSigStartValue" SG_ 642 VHL_5_LEFT_AZIMUTH_RATE 4095;

BA_ "GenSigSendType" SG_ 642 VHL_5_LEFT_AZIMUTH_RATE 1;
BA_ "GenSigStartValue" SG_ 642 RFL_1_RIGHT_ANGLE 8191;

BA_ "GenSigSendType" SG_ 642 RFL_1_RIGHT_ANGLE 1;
BA_ "GenSigStartValue" SG_ 642 RFL_2_RIGHT_ANGLE 8191;

BA_ "GenSigSendType" SG_ 642 RFL_2_RIGHT_ANGLE 1;
BA_ "GenSigStartValue" SG_ 642 RFL_3_RIGHT_ANGLE 8191;

BA_ "GenSigSendType" SG_ 642 RFL_3_RIGHT_ANGLE 1;
BA_ "GenSigStartValue" SG_ 642 RFL_1_LEFT_ANGLE 8191;

BA_ "GenSigSendType" SG_ 642 RFL_1_LEFT_ANGLE 1;
BA_ "GenSigStartValue" SG_ 642 RFL_2_LEFT_ANGLE 8191;

BA_ "GenSigSendType" SG_ 642 RFL_2_LEFT_ANGLE 1;
BA_ "GenSigStartValue" SG_ 642 RFL_3_LEFT_ANGLE 8191;

BA_ "GenSigSendType" SG_ 642 RFL_3_LEFT_ANGLE 1;
BA_ "GenSigStartValue" SG_ 642 RFL_1_LEFT_AZIMUTH_RATE 2047;

BA_ "GenSigSendType" SG_ 642 RFL_1_LEFT_AZIMUTH_RATE 1;
BA_ "GenSigStartValue" SG_ 642 RFL_2_LEFT_AZIMUTH_RATE 2047;

BA_ "GenSigSendType" SG_ 642 RFL_2_LEFT_AZIMUTH_RATE 1;
BA_ "GenSigStartValue" SG_ 642 RFL_3_LEFT_AZIMUTH_RATE 2047;

BA_ "GenSigSendType" SG_ 642 RFL_3_LEFT_AZIMUTH_RATE 1;
BA_ "GenSigStartValue" SG_ 642 RFL_1_RIGHT_AZIMUTH_RATE 2047;

BA_ "GenSigSendType" SG_ 642 RFL_1_RIGHT_AZIMUTH_RATE 1;
BA_ "GenSigStartValue" SG_ 642 RFL_2_RIGHT_AZIMUTH_RATE 2047;

BA_ "GenSigSendType" SG_ 642 RFL_2_RIGHT_AZIMUTH_RATE 1;
BA_ "GenSigStartValue" SG_ 642 RFL_3_RIGHT_AZIMUTH_RATE 2047;

BA_ "GenSigSendType" SG_ 642 RFL_3_RIGHT_AZIMUTH_RATE 1;
BA_ "GenSigStartValue" SG_ 642 RFL_3_DISTANCE 511;

BA_ "GenSigSendType" SG_ 642 RFL_3_DISTANCE 1;
BA_ "GenSigStartValue" SG_ 642 RFL_2_DISTANCE 511;

BA_ "GenSigSendType" SG_ 642 RFL_2_DISTANCE 1;
BA_ "GenSigStartValue" SG_ 642 RFL_1_DISTANCE 511;

BA_ "GenSigSendType" SG_ 642 RFL_1_DISTANCE 1;

BA_ "GenSigSendType" SG_ 642 VHL_1_VDID 1;

BA_ "GenSigSendType" SG_ 642 VHL_2_VDID 1;

BA_ "GenSigSendType" SG_ 642 VHL_3_VDID 1;

BA_ "GenSigSendType" SG_ 642 VHL_4_VDID 1;

BA_ "GenSigSendType" SG_ 642 VHL_5_VDID 1;

BA_ "GenSigSendType" SG_ 642 VHL_1_ID 1;

BA_ "GenSigSendType" SG_ 642 VHL_2_ID 1;

BA_ "GenSigSendType" SG_ 642 VHL_3_ID 1;

BA_ "GenSigSendType" SG_ 642 VHL_4_ID 1;

BA_ "GenSigSendType" SG_ 642 VHL_5_ID 1;

BA_ "GenSigSendType" SG_ 642 RFL_1_ID 1;

BA_ "GenSigSendType" SG_ 642 RFL_2_ID 1;

BA_ "GenSigSendType" SG_ 642 RFL_3_ID 1;

BA_ "GenSigSendType" SG_ 645 FREE_4 1;
BA_ "GenSigStartValue" SG_ 645 ACC_FRONT_TARGET_DISTANCE 250;

BA_ "GenSigSendType" SG_ 645 ACC_FRONT_TARGET_DISTANCE 1;

BA_ "GenSigSendType" SG_ 645 ACC_ACCEL_SETPOINT_REQ 1;

BA_ "GenSigSendType" SG_ 645 ACC_FRONT_TARGET_RELARIVE_ACCEL 1;

BA_ "GenSigSendType" SG_ 645 ACC_FRONT_TARGET_RELARIVE_SPEED 1;
BA_ "GenSigStartValue" SG_ 645 ACC_DESIRED_INTERVEHICLE_DIST 255;

BA_ "GenSigSendType" SG_ 645 ACC_DESIRED_INTERVEHICLE_DIST 1;

BA_ "GenSigSendType" SG_ 645 ACC_FRONT_TARGET_CRITICITY 1;

BA_ "GenSigSendType" SG_ 645 ACC_FRONT_TARGET_POSITION 1;

BA_ "GenSigSendType" SG_ 645 ACC_FRONT_TARGET_TYPE 1;

BA_ "GenSigSendType" SG_ 645 E2E_CRC_LRCF_DATA_9 1;

BA_ "GenSigSendType" SG_ 645 E2E_ALIVE_LRCF_DATA_9 1;

BA_ "GenSigSendType" SG_ 645 EGO_LANE_WIDTH 1;

BA_ "GenSigSendType" SG_ 645 EGO_LANE_NUMBER 1;

BA_ "GenSigSendType" SG_ 645 FRONT_EGO_LANE_LOWER_LIMIT 1;

BA_ "GenSigSendType" SG_ 645 FRONT_EGO_LANE_UPPER_LIMIT 1;

BA_ "GenSigSendType" SG_ 645 EGO_LANE_QUALITY 1;
BA_ "GenSigStartValue" SG_ 645 FRONT_EGO_LANE_A0_POLY_COEF 34359741121;

BA_ "GenSigSendType" SG_ 645 FRONT_EGO_LANE_A0_POLY_COEF 1;
BA_ "GenSigStartValue" SG_ 645 FRONT_EGO_LANE_A1_POLY_COEF 34359741121;

BA_ "GenSigSendType" SG_ 645 FRONT_EGO_LANE_A1_POLY_COEF 1;
BA_ "GenSigStartValue" SG_ 645 FRONT_EGO_LANE_A2_POLY_COEF 34359741121;

BA_ "GenSigSendType" SG_ 645 FRONT_EGO_LANE_A2_POLY_COEF 1;
BA_ "GenSigStartValue" SG_ 645 FRONT_EGO_LANE_A3_POLY_COEF 34359741121;

BA_ "GenSigSendType" SG_ 645 FRONT_EGO_LANE_A3_POLY_COEF 1;

BA_ "GenSigSendType" SG_ 2654486657 SOURCENODEIDENTIFIER 2;

BA_ "GenSigSendType" SG_ 2654486657 CBV_BIT0_REPEATMESSAGEREQUESTBIT 2;

BA_ "GenSigSendType" SG_ 2654486657 CBV_BIT1 2;

BA_ "GenSigSendType" SG_ 2654486657 CBV_BIT2 2;

BA_ "GenSigSendType" SG_ 2654486657 CBV_BIT3_NMCOORDINATORBIT 2;

BA_ "GenSigSendType" SG_ 2654486657 CBV_BIT4_ACTIVEWAKEUPBIT 2;

BA_ "GenSigSendType" SG_ 2654486657 CBV_BIT5 2;

BA_ "GenSigSendType" SG_ 2654486657 CBV_BIT6_PARTIALNTWINFBIT 2;

BA_ "GenSigSendType" SG_ 2654486657 CBV_BIT7 2;

BA_ "GenSigSendType" SG_ 282 E2E_ALIVE_ORC_DATA_1_11A 1;

BA_ "GenSigSendType" SG_ 282 E2E_CRC_ORC_DATA_1_11A 1;

BA_ "GenSigSendType" SG_ 282 LAT_ACCELERATION_FAULT_STS 1;

BA_ "GenSigSendType" SG_ 282 LONG_ACCELERATION_FAULT_STS 1;

BA_ "GenSigSendType" SG_ 282 YAW_RATE_FAULT_STS 1;
BA_ "GenSigStartValue" SG_ 282 YAW_RATE 4095;

BA_ "GenSigSendType" SG_ 282 YAW_RATE 1;
BA_ "GenSigStartValue" SG_ 282 LAT_ACCELERATION 4095;

BA_ "GenSigSendType" SG_ 282 LAT_ACCELERATION 1;
BA_ "GenSigStartValue" SG_ 282 LONG_ACCELERATION 4095;

BA_ "GenSigSendType" SG_ 282 LONG_ACCELERATION 1;
BA_ "Accuracy" SG_ 2654339201 EOL_LRCF "-";

BA_ "GenSigSendType" SG_ 2654339201 EOL_LRCF 1;

BA_ "GenSigSendType" SG_ 2654339201 CurrentCanNMState_FD15_LRCF 1;

BA_ "GenSigSendType" SG_ 2654503041 NM_STATE 1;

BA_ "GenSigSendType" SG_ 2654503041 CurrentCanNMState_FD15_LRCF 1;

BA_ "GenSigSendType" SG_ 2654503041 FREE_3 1;

BA_ "GenSigSendType" SG_ 2654502924 NM_STATE 1;

BA_ "GenSigSendType" SG_ 2654502924 CurrentCanNMState_FD15_ZCU_F 1;

BA_ "GenSigSendType" SG_ 2654502924 FREE_3 1;
BA_ "GenSigStartValue" SG_ 129 VERSION_DATA 85;

BA_ "GenSigSendType" SG_ 129 VERSION_DATA 2;
BA_ "Event trans." SG_ 121 ECU_Code_ACK 0;

BA_ "GenSigSendType" SG_ 121 ECU_Code_ACK 2;
BA_ "Event trans." SG_ 121 Rep_UCE 0;

BA_ "GenSigSendType" SG_ 121 Rep_UCE 2;

BA_ "GenSigSendType" SG_ 556 ACC_STATE_INFO_FOR_CHASSIS 1;

BA_ "GenSigSendType" SG_ 556 LANE_ASSIT_STATE_FROM_LAS 1;

BA_ "GenSigSendType" SG_ 556 TORQUE_FACTOR_REQUEST_FROM_LAS 1;
BA_ "GenSigStartValue" SG_ 556 YAW_RATE_REQUEST_SETPOINT_LAS 1000;

BA_ "GenSigSendType" SG_ 556 YAW_RATE_REQUEST_SETPOINT_LAS 1;
BA_ "GenSigStartValue" SG_ 556 PACC_ACCEL_LONGI_REQUEST 500;

BA_ "GenSigSendType" SG_ 556 PACC_ACCEL_LONGI_REQUEST 1;

BA_ "GenSigSendType" SG_ 556 PACC_BEVENT_IN_PROGRESS 1;
BA_ "Event trans." SG_ 1546 DRIVER_DOOR_OPEN_STATUS 0;

BA_ "GenSigSendType" SG_ 1546 DRIVER_DOOR_OPEN_STATUS 0;

BA_ "GenSigSendType" SG_ 1546 EXT_TEMP_FILTRED_DEG_C 0;

BA_ "GenSigSendType" SG_ 1546 HEADLAMP_WITH_WIPER_REQ 0;
BA_ "GenSigStartValue" SG_ 1546 TRAILER_CONNECTION_STS 2;

BA_ "GenSigSendType" SG_ 1546 TRAILER_CONNECTION_STS 0;

BA_ "GenSigSendType" SG_ 1546 RCTA_DRIVER_INHIBITION_REQUEST 0;
BA_ "Event trans." SG_ 1546 PASSENGER_DOOR_OPEN_STATUS 0;

BA_ "GenSigSendType" SG_ 1546 PASSENGER_DOOR_OPEN_STATUS 0;
BA_ "Event trans." SG_ 1546 TURN_SIGNAL_STS 0;

BA_ "GenSigSendType" SG_ 1546 TURN_SIGNAL_STS 0;

BA_ "GenSigSendType" SG_ 1546 DAY_NIGHT_STATUS 0;
BA_ "GenSigStartValue" SG_ 1546 FRONT_WIPING_ST 7;

BA_ "GenSigSendType" SG_ 1546 FRONT_WIPING_ST 0;

BA_ "GenSigSendType" SG_ 1546 FRT_WIPING_CONF 0;

BA_ "GenSigSendType" SG_ 1546 DRIVING_MODE_POWERTRAIN_REQ 0;

BA_ "GenSigSendType" SG_ 1032 DRIVER_SEATBELT_BUCKLE_DATA 0;

BA_ "GenSigSendType" SG_ 1032 DRIVER_SEATBELT_BUCKLE_SECU_DATA 0;

BA_ "GenSigSendType" SG_ 1032 ROW1_P_SEATBELT_BUCKLE_DATA 0;

BA_ "GenSigSendType" SG_ 1032 ROW1_P_SEATBELT_BUCKLE_SECU_DATA 0;
BA_ "Event trans." SG_ 1032 TURN_INDICATOR_DRIVER_DMD 0;

BA_ "GenSigSendType" SG_ 1032 TURN_INDICATOR_DRIVER_DMD 0;

BA_ "GenSigSendType" SG_ 1032 VIN_INFORMATION 0;
BA_ "GenSigStartValue" SG_ 1289 BLINDSPOTDETECTION_DRIVERREQUEST 1;

BA_ "GenSigSendType" SG_ 1289 BLINDSPOTDETECTION_DRIVERREQUEST 0;

BA_ "GenSigSendType" SG_ 1034 FREE_4 0;
BA_ "Event trans." SG_ 1034 VEHICLE_IGNITION_STATUS 0;

BA_ "GenSigSendType" SG_ 1034 VEHICLE_IGNITION_STATUS 0;
BA_ "Event trans." SG_ 1034 PROPULSION_OFF_REQUEST 0;

BA_ "GenSigSendType" SG_ 1034 PROPULSION_OFF_REQUEST 0;
BA_ "GenSigStartValue" SG_ 1034 VEHICLE_MODE_CONFIGURATION 4;

BA_ "GenSigSendType" SG_ 1034 VEHICLE_MODE_CONFIGURATION 0;

BA_ "GenSigSendType" SG_ 1034 E2E_CRC_ZCU_CL_GLOBAL_DATA_40A 0;

BA_ "GenSigSendType" SG_ 1034 E2E_ALIVE_ZCU_CL_GLOBAL_DATA_40A 0;

BA_ "GenSigSendType" SG_ 1034 DAY_LIGHT_MODE_CMD 0;
BA_ "Event trans." SG_ 1034 BACK_LIGHT_INTENSITY_CMD 0;

BA_ "GenSigSendType" SG_ 1034 BACK_LIGHT_INTENSITY_CMD 0;
BA_ "Event trans." SG_ 1550 ESC_TCS_FAILSTATUS 0;

BA_ "GenSigSendType" SG_ 1550 ESC_TCS_FAILSTATUS 0;

BA_ "GenSigSendType" SG_ 1550 FREE_4 0;

BA_ "GenSigSendType" SG_ 1550 WHEEL_SPARE_SIZEDETECTION_STATE 0;

BA_ "GenSigSendType" SG_ 1550 E2E_CRC_ZCU_F_DATA_15 0;

BA_ "GenSigSendType" SG_ 1550 E2E_ALIVE_ZCU_F_DATA_15 0;

BA_ "GenSigSendType" SG_ 1055 HOD_FAIL_STATUS 0;

BA_ "GenSigSendType" SG_ 1055 STEERWHEEL_HELD_BY_DRIVER_OPTI 0;

BA_ "GenSigSendType" SG_ 270 FREE_4 1;

BA_ "GenSigSendType" SG_ 270 ACCEL_PEDAL_PERCENT_PWT 1;

BA_ "GenSigSendType" SG_ 270 PRND_ENGAGED_FOR_DISPLAY 1;

BA_ "GenSigSendType" SG_ 270 PRND_TARGET_STATE 1;

BA_ "GenSigSendType" SG_ 270 SHIFT_LEVER_POSITION_PWT 1;

BA_ "GenSigSendType" SG_ 270 E2E_CRC_ZCU_F_DATA_9 1;

BA_ "GenSigSendType" SG_ 270 E2E_ALIVE_ZCU_F_DATA_9 1;
BA_ "GenSigStartValue" SG_ 270 HANDWHEEL_STEERING_ANGLE_VALUE_S 16383;

BA_ "GenSigSendType" SG_ 270 HANDWHEEL_STEERING_ANGLE_VALUE_S 1;

BA_ "GenSigSendType" SG_ 270 LXA_STEERING_STATE_S 1;

BA_ "GenSigSendType" SG_ 270 STEERING_ASSIST_STATUS_S 1;
BA_ "GenSigStartValue" SG_ 270 STEERINGWHEEL_ANGLE_REL_FRT_VA_S 32737;

BA_ "GenSigSendType" SG_ 270 STEERINGWHEEL_ANGLE_REL_FRT_VA_S 1;
BA_ "GenSigStartValue" SG_ 270 STEERINGWHEEL_ROT_VELOCITY_FRT_S 2050;

BA_ "GenSigSendType" SG_ 270 STEERINGWHEEL_ROT_VELOCITY_FRT_S 1;
BA_ "GenSigStartValue" SG_ 270 ACC_STATE_INFO_IN_POWERTRAIN 1;

BA_ "GenSigSendType" SG_ 270 ACC_STATE_INFO_IN_POWERTRAIN 1;
BA_ "GenSigStartValue" SG_ 270 STEERINGWHEEL_ANGLE_FRONT_VAL_S 16383;

BA_ "GenSigSendType" SG_ 270 STEERINGWHEEL_ANGLE_FRONT_VAL_S 1;

BA_ "GenSigSendType" SG_ 270 CRUISE_CONTROL_STATUS 1;

BA_ "GenSigSendType" SG_ 1035 FREE_4 0;
BA_ "Event trans." SG_ 1035 PROPULSION_SYSTEM_ACTIVE 0;

BA_ "GenSigSendType" SG_ 1035 PROPULSION_SYSTEM_ACTIVE 0;

BA_ "GenSigSendType" SG_ 1035 E2E_CRC_ZCU_F_GLOBAL_DATA 0;

BA_ "GenSigSendType" SG_ 1035 E2E_ALIVE_ZCU_F_GLOBAL_DATA_40B 0;
BA_ "GenSigStartValue" SG_ 1035 TOTAL_ODOMETER 16777215;

BA_ "GenSigSendType" SG_ 1035 TOTAL_ODOMETER 0;

BA_ "GenSigSendType" SG_ 1035 DIAGMUX 0;
BA_ "GenSigStartValue" SG_ 1035 TRUSTED_TIME_YEAR 65535;

BA_ "GenSigSendType" SG_ 1035 TRUSTED_TIME_YEAR 0;
BA_ "GenSigStartValue" SG_ 1035 TRUSTED_TIME_MONTH 15;

BA_ "GenSigSendType" SG_ 1035 TRUSTED_TIME_MONTH 0;
BA_ "GenSigStartValue" SG_ 1035 TRUSTED_TIME_DAY 31;

BA_ "GenSigSendType" SG_ 1035 TRUSTED_TIME_DAY 0;
BA_ "GenSigStartValue" SG_ 1035 TRUSTED_TIME_HOUR 31;

BA_ "GenSigSendType" SG_ 1035 TRUSTED_TIME_HOUR 0;
BA_ "GenSigStartValue" SG_ 1035 TRUSTED_TIME_MINUTE 63;

BA_ "GenSigSendType" SG_ 1035 TRUSTED_TIME_MINUTE 0;
BA_ "GenSigStartValue" SG_ 1035 TRUSTED_TIME_SECOND 63;

BA_ "GenSigSendType" SG_ 1035 TRUSTED_TIME_SECOND 0;

BA_ "GenSigSendType" SG_ 1035 SHUTDOWN_NTW_FD_CAN14 0;

BA_ "GenSigSendType" SG_ 1035 SHUTDOWN_NTW_FD_CAN5 0;
VAL_ 1152 SMARTE_COAST_FR_TAR_CONFI 0 "Low_None" 1 "Medium" 2 "High" 3 "Unavailable";
VAL_ 897 FRONT_CAMERA_RIGHTLINE_CURV_DERI 65534 "Invalid" 65535 "Unavailable";
VAL_ 897 FRONT_CAMERA_LEFTLINE_CURV_DERI 65534 "Invalid" 65535 "Unavailable";
VAL_ 897 FRONT_CAMERA_LEFTLINE_DISTANCE 2046 "Invalid" 2047 "Unavailable";
VAL_ 897 FRONT_CAMERA_RIGHTLINE_DISTANCE 2046 "Invalid" 2047 "Unavailable";
VAL_ 897 FRONT_CAMERA_LEFTLINE_CURVATURE 65534 "Invalid" 65535 "Unavailable";
VAL_ 897 FRONT_CAMERA_RIGHTLINE_CURVATURE 65534 "Invalid" 65535 "Unavailable";
VAL_ 897 FRONT_CAMERA_RIGHTLINE_DETECTION 0 "Not valid" 1 "Valid";
VAL_ 897 FRONT_CAMERA_LEFTLINE_DETECTION 0 "Not valid" 1 "Valid";
VAL_ 897 FRONT_CAMERA_LANE_STATUS 0 "FullyOperational" 1 "SensorBlocked" 2 "Degraded" 3 "Defect";
VAL_ 897 GFHB_CAMERA_STATUS 0 "Available" 1 "Suspended_by_visibility" 2 "Suspended_by_lum" 3 "Suspended_by_speed" 4 "Suspended_in_lit_zone" 5 "Unavailable" 6 "Reserved" 7 "Reserved";
VAL_ 897 FRONT_CAM_RIGHT_LINE_TYPE 0 "NotDetected" 1 "SingleDashed" 2 "SingleSolid" 3 "DoubleDashedDashed" 4 "DoubleDashedSolid" 5 "DoubleSolidDashed" 6 "DoubleSolidSolid" 7 "Unknown";
VAL_ 897 FRONT_CAM_LEFT_LINE_TYPE 0 "NotDetected" 1 "SingleDashed" 2 "SingleSolid" 3 "DoubleDashedDashed" 4 "DoubleDashedSolid" 5 "DoubleSolidDashed" 6 "DoubleSolidSolid" 7 "Unknown";
VAL_ 897 FRONT_CAM_RIGHT_LINE_MARK_QLTY 0 "Low1" 1 "Low2" 2 "Medium" 3 "High";
VAL_ 897 FRONT_CAM_LEFT_LINE_MARK_QLTY 0 "Low1" 1 "Low2" 2 "Medium" 3 "High";
VAL_ 897 FRONT_CAM_LEFT_LINE_HEADING_ANG 4094 "Invalid" 4095 "Unavailable";
VAL_ 897 FRONT_CAM_RIGHT_LINE_HEADING_ANG 4094 "Invalid" 4095 "Unavailable";
VAL_ 897 FRONT_CAM_NEXT_LEFT_LINE_TYPE 0 "NotDetected" 1 "SingleDashed" 2 "SingleSolid" 3 "DoubleDashedDashed" 4 "DoubleDashedSolid" 5 "DoubleSolidDashed" 6 "DoubleSolidSolid" 7 "Unknown";
VAL_ 897 FRONT_CAM_NEXT_RIGHT_LINE_TYPE 0 "NotDetected" 1 "SingleDashed" 2 "SingleSolid" 3 "DoubleDashedDashed" 4 "DoubleDashedSolid" 5 "DoubleSolidDashed" 6 "DoubleSolidSolid" 7 "Unknown";
VAL_ 897 FRONTCAM_NEXTRIGHTLINE_CURV_DERI 65534 "Invalid" 65535 "Unavailable";
VAL_ 897 FRONTCAM_NEXTLEFTLINE_CURV_DERI 65534 "Invalid" 65535 "Unavailable";
VAL_ 897 FRONTCAM_NEXT_LEFTLINE_MARK_QLTY 0 "Low1" 1 "Low2" 2 "Medium" 3 "High";
VAL_ 897 FRONTCAM_NEXTRIGHTLINE_MARKQLTY 0 "Low1" 1 "Low2" 2 "Medium" 3 "High";
VAL_ 897 FRONT_CAM_RIGHT_LANE_DIRECTION 0 "Unknown  0x1" 1 "Same_Direction_As_the Ego" 2 "Opposite_Direction_As_the Ego" 3 "Mixed_direction Ego";
VAL_ 897 FRONT_CAM_LEFT_LANE_DIRECTION 0 "Unknown  0x1" 1 "Same_Direction_As_the Ego" 2 "Opposite_Direction_As_the Ego" 3 "Mixed_direction Ego";
VAL_ 897 FRONTCAM_NXTLEFTLINE_ROAD_EDGE 0 "Flat" 1 "Elevated_Structure" 2 "Curb" 3 "Cones_poles" 4 "Parking_cars" 5 "No_Roadegde" 6 "Reserved" 7 "Reserved";
VAL_ 897 FRONTCAM_NXTRIGHTLINE_ROAD_EDGE 0 "Flat" 1 "Elevated_Structure" 2 "Curb" 3 "Cones_poles" 4 "Parking_cars" 5 "No_Roadegde" 6 "Reserved" 7 "Reserved";
VAL_ 897 FRONTCAM_LEFTLINE_ROAD_EDGE 0 "Flat" 1 "Elevated_Structure" 2 "Curb" 3 "Cones_poles" 4 "Parking_cars" 5 "No_Roadegde" 6 "Reserved" 7 "Reserved";
VAL_ 897 FRONTCAM_RIGHTLINE_ROAD_EDGE 0 "Flat" 1 "Elevated_Structure" 2 "Curb" 3 "Cones_poles" 4 "Parking_cars" 5 "No_Roadegde" 6 "Reserved" 7 "Reserved";
VAL_ 897 FRONTCAM_LEFTLANE_DETECTION 0 "NO_LANE_ DETECTED" 1 "LANE_DETECTED";
VAL_ 897 FRONTCAM_RIGHTLANE_DETECTION 0 "NO_LANE_ DETECTED" 1 "LANE_DETECTED";
VAL_ 897 FRONTCAM_LEFT_HIGHWAY_EXIT 0 "No_HWE" 1 "HWE_On_The_Right " 2 "HWE_On_The_Left" 3 "Reserved";
VAL_ 897 FRONTCAM_NXT_LEFTLINE_COLOR 0 "Unknown" 1 "White" 2 "Yellow or Red or Orange" 3 "Blue or Green";
VAL_ 897 FRONTCAM_NXT_RIGHTTLINE_COLOR 0 "Unknown" 1 "White" 2 "Yellow or Red or Orange" 3 "Blue or Green";
VAL_ 897 FRONTCAM_LEFTLINE_COLOR 0 "Unknown" 1 "White" 2 "Yellow or Red or Orange" 3 "Blue or Green";
VAL_ 897 FRONTCAM_RIGHTTLINE_COLOR 0 "Unknown" 1 "White" 2 "Yellow or Red or Orange" 3 "Blue or Green";
VAL_ 897 FRONTCAM_NXT_LEFTLINE_DETECT_STS 0 "NotValid" 1 "Valid";
VAL_ 897 FRONTCAM_NXTRIGHTLINE_DETECT_STS 0 "NotValid" 1 "Valid";
VAL_ 897 FRONTCAM_LANE_CROSSING 0 "No_Change" 1 "Crossing_Left" 2 "Crossing_Right" 3 "Reserved";
VAL_ 897 FRONTCAM_EGO_OBJ_CIPV 0 "TRUE" 1 "FALSE";
VAL_ 897 FRONTCAM_EGO2_OBJ_CIPV 0 "TRUE" 1 "FALSE";
VAL_ 897 FRONTCAM_L1_OBJ_CIPV 0 "TRUE" 1 "FALSE";
VAL_ 897 FRONTCAM_L2_OBJ_CIPV 0 "TRUE" 1 "FALSE";
VAL_ 897 FRONTCAM_L3_OBJ_CIPV 0 "TRUE" 1 "FALSE";
VAL_ 897 FRONTCAM_R1_OBJ_CIPV 0 "TRUE" 1 "FALSE";
VAL_ 897 FRONTCAM_R2_OBJ_CIPV 0 "TRUE" 1 "FALSE";
VAL_ 897 FRONTCAM_R3_OBJ_CIPV 0 "TRUE" 1 "FALSE";
VAL_ 640 VHL_1_CL_SUB_TYPE 0 "ONCOMING" 1 "TAILLIGHT" 2 "LEFT_ONCOMING" 3 "RIGHT_ONCOMING" 4 "LEFT_AND_RIGHT_ONCOMING" 5 "LEFT_AND_RIGHT_TAILLIGHT" 6 "INVALID" 7 "UNAVAILABLE";
VAL_ 640 VHL_4_CL_SUB_TYPE 0 "ONCOMING" 1 "TAILLIGHT" 2 "LEFT_ONCOMING" 3 "RIGHT_ONCOMING" 4 "LEFT_AND_RIGHT_ONCOMING" 5 "LEFT_AND_RIGHT_TAILLIGHT" 6 "INVALID" 7 "UNAVAILABLE";
VAL_ 640 VHL_5_CL_SUB_TYPE 0 "ONCOMING" 1 "TAILLIGHT" 2 "LEFT_ONCOMING" 3 "RIGHT_ONCOMING" 4 "LEFT_AND_RIGHT_ONCOMING" 5 "LEFT_AND_RIGHT_TAILLIGHT" 6 "INVALID" 7 "UNAVAILABLE";
VAL_ 640 VHL_2_CL_SUB_TYPE 0 "ONCOMING" 1 "TAILLIGHT" 2 "LEFT_ONCOMING" 3 "RIGHT_ONCOMING" 4 "LEFT_AND_RIGHT_ONCOMING" 5 "LEFT_AND_RIGHT_TAILLIGHT" 6 "INVALID" 7 "UNAVAILABLE";
VAL_ 640 VHL_3_CL_SUB_TYPE 0 "ONCOMING" 1 "TAILLIGHT" 2 "LEFT_ONCOMING" 3 "RIGHT_ONCOMING" 4 "LEFT_AND_RIGHT_ONCOMING" 5 "LEFT_AND_RIGHT_TAILLIGHT" 6 "INVALID" 7 "UNAVAILABLE";
VAL_ 640 VHL_1_TYPE 0 "ONCOMING" 1 "COUPLE_ONCOMING" 2 "TAILLIGHT" 3 "COUPLE_TAILLIGHT" 4 "COUPLE_OC_CLEARANCE" 5 "INVALID" 6 "UNAVAILABLE" 7 "Reserved";
VAL_ 640 VHL_2_TYPE 0 "ONCOMING" 1 "COUPLE_ONCOMING" 2 "TAILLIGHT" 3 "COUPLE_TAILLIGHT" 4 "COUPLE_OC_CLEARANCE" 5 "INVALID" 6 "UNAVAILABLE" 7 "Reserved";
VAL_ 640 VHL_3_TYPE 0 "ONCOMING" 1 "COUPLE_ONCOMING" 2 "TAILLIGHT" 3 "COUPLE_TAILLIGHT" 4 "COUPLE_OC_CLEARANCE" 5 "INVALID" 6 "UNAVAILABLE" 7 "Reserved";
VAL_ 640 VHL_4_TYPE 0 "ONCOMING" 1 "COUPLE_ONCOMING" 2 "TAILLIGHT" 3 "COUPLE_TAILLIGHT" 4 "COUPLE_OC_CLEARANCE" 5 "INVALID" 6 "UNAVAILABLE" 7 "Reserved";
VAL_ 640 VHL_5_TYPE 0 "ONCOMING" 1 "COUPLE_ONCOMING" 2 "TAILLIGHT" 3 "COUPLE_TAILLIGHT" 4 "COUPLE_OC_CLEARANCE" 5 "INVALID" 6 "UNAVAILABLE" 7 "Reserved";
VAL_ 642 TRAFFIC_IS_DETECTED 0 "FALSE" 1 "TRUE" 2 "INVALID" 3 "UNAVAILABLE";
VAL_ 645 ACC_FRONT_TARGET_POSITION 0 "None" 1 "Object_Position1" 2 "Object_Position2" 3 "Object_Position3" 4 "Object_Position4" 5 "Object_Position5" 6 "Object_Position6" 7 "Object_Position7" 8 "Object_Position8" 9 "Object_Position9" 10 "Object_Position10" 11 "Object_Position11" 12 "Object_Position12" 13 "Object_Position13" 14 "Object_Position14" 15 "Object_Position15" 16 "Object_Position16" 17 "Object_Position17" 18 "Object_Position18" 19 "Object_Position19" 20 "Object_Position20" 21 "Object_Position21" 22 "Object_Position22" 23 "Object_Position23" 24 "Object_Position24" 25 "Object_Position25" 26 "Object_Position26" 27 "Object_Position27" 28 "Object_Position28" 29 "Object_Position29" 30 "Object_Position30" 31 "Object_Position31" 32 "Object_Position32" 33 "Object_Position33" 34 "Object_Position34" 35 "Object_Position35" 36 "Object_Position36" 37 "Object_Position37" 38 "Object_Position38" 39 "Object_Position39" 40 "Object_Position40" 41 "Object_Position41" 42 "Object_Position42" 43 "Object_Position43" 44 "Object_Position44" 45 "Object_Position45" 46 "Object_Position46" 47 "Object_Position47" 48 "Object_Position48" 49 "Object_Position49" 50 "Object_Position50" 51 "Object_Position51" 52 "Object_Position52" 53 "Object_Position53" 54 "Object_Position54" 55 "Object_Position55" 56 "Object_Position56" 57 "Object_Position57" 58 "Object_Position58" 59 "Object_Position59" 60 "Object_Position60" 61 "Object_Position61" 62 "Object_Position62" 63 "Object_Position63";
VAL_ 645 ACC_FRONT_TARGET_TYPE 0 "Unknown" 1 "Truck" 2 "Car" 3 "MotorBike" 4 "Bicycle" 5 "Pedestrian" 6 "Undecided" 7 "Reserved";
VAL_ 645 EGO_LANE_NUMBER 0 "Unknown" 1 "Most_right_Lane" 2 "Middle_Lanes" 3 "Most_Left_Lane";
VAL_ 645 EGO_LANE_QUALITY 0 "Low1" 1 "Low2" 2 "Medium" 3 "High";
VAL_ 282 LAT_ACCELERATION_FAULT_STS 0 "Fail_Not_Present" 1 "Fail_Present";
VAL_ 282 LONG_ACCELERATION_FAULT_STS 0 "Fail_Not_Present" 1 "Fail_Present";
VAL_ 282 YAW_RATE_FAULT_STS 0 "Fail_Not_Present" 1 "Fail_Present";
VAL_ 2654339201 EOL_LRCF 0 "No_EOL_Programming" 1 "EOL_Programming";
VAL_ 2654339201 CurrentCanNMState_FD15_LRCF 0 "Reserved" 1 "Bus-Sleep State" 2 "Prepare-Bus State" 3 "Ready-Sleep State" 4 "Normal Operation State" 5 "Repeat Message State" 6 "Reserved" 7 "Reserved" 8 "Reserved" 9 "Reserved" 10 "Reserved" 11 "Reserved" 12 "Reserved" 13 "Reserved" 14 "Reserved" 15 "Reserved";
VAL_ 2654503041 NM_STATE 0 "NM inactive" 1 "NM active";
VAL_ 2654503041 CurrentCanNMState_FD15_LRCF 0 "Reserved" 1 "Bus-Sleep State" 2 "Prepare-Bus State" 3 "Ready-Sleep State" 4 "Normal Operation State" 5 "Repeat Message State" 6 "Reserved" 7 "Reserved" 8 "Reserved" 9 "Reserved" 10 "Reserved" 11 "Reserved" 12 "Reserved" 13 "Reserved" 14 "Reserved" 15 "Reserved";
VAL_ 2654502924 NM_STATE 0 "NM inactive" 1 "NM active";
VAL_ 2654502924 CurrentCanNMState_FD15_ZCU_F 0 "Reserved" 1 "Bus-Sleep State" 2 "Prepare-Bus State" 3 "Ready-Sleep State" 4 "Normal Operation State" 5 "Repeat Message State" 6 "Reserved" 7 "Reserved" 8 "Reserved" 9 "Reserved" 10 "Reserved" 11 "Reserved" 12 "Reserved" 13 "Reserved" 14 "Reserved" 15 "Reserved";
VAL_ 121 Rep_UCE 0 "NOT_ACKNOWLEDGED" 1 "ACKNOWLEDGED";
VAL_ 556 ACC_STATE_INFO_FOR_CHASSIS 0 "Inactive" 1 "Active" 2 "ActiveBrakeOnly" 3 "ActiveStandstill";
VAL_ 556 LANE_ASSIT_STATE_FROM_LAS 0 "UNAVAILABLE" 1 "UNSELECTED" 2 "SELECTED" 3 "SUSPENDED" 4 "ACTIVE" 5 "DEFECT" 6 "Reserved" 7 "Reserved";
VAL_ 556 PACC_BEVENT_IN_PROGRESS 0 "NO_REQUEST" 1 "REQUEST";
VAL_ 1546 DRIVER_DOOR_OPEN_STATUS 0 "Closed" 1 "Open";
VAL_ 1546 HEADLAMP_WITH_WIPER_REQ 0 "False" 1 "True";
VAL_ 1546 TRAILER_CONNECTION_STS 0 "DISCONNECTED" 1 "CONNECTED" 2 "UNAVAILABLE" 3 "Reserved";
VAL_ 1546 RCTA_DRIVER_INHIBITION_REQUEST 0 "Inhibit" 1 "Enable";
VAL_ 1546 PASSENGER_DOOR_OPEN_STATUS 0 "Closed" 1 "Open";
VAL_ 1546 TURN_SIGNAL_STS 0 "Off" 1 "Right" 2 "Left" 3 "Both";
VAL_ 1546 DAY_NIGHT_STATUS 0 "NIGHT" 1 "DAY";
VAL_ 1546 FRONT_WIPING_ST 0 "Unknown" 1 "Parking" 2 "Depressed_park" 3 "Low_wipe" 4 "High_wipe" 5 "Speed1" 6 "Speed2" 7 "Speed3" 8 "Speed4" 9 "Speed5" 10 "Speed6" 11 "Speed7" 12 "Speed8" 13 "Speed9" 14 "Speed10" 15 "Speed11" 16 "Speed12" 17 "Speed13" 18 "Speed14" 19 "Service_Wiper" 20 "Moving" 21 "Not_moving";
VAL_ 1546 FRT_WIPING_CONF 0 "False" 1 "True";
VAL_ 1546 DRIVING_MODE_POWERTRAIN_REQ 0 "Auto" 1 "Auto Fault" 2 "Rock" 3 "Track" 4 "Snow" 5 "Offroad" 6 "Eco" 7 "Corsa" 8 "Sport" 9 "Mud Sand" 10 "Mud" 11 "Sand" 12 "Valet" 13 "Custom" 14 "Tow" 15 "Drag" 16 "Baja" 17 "Reserved" 18 "Reserved" 19 "Reserved" 20 "Reserved" 21 "Reserved" 22 "Reserved" 23 "Reserved" 24 "Reserved" 25 "Reserved" 26 "Reserved" 27 "Reserved" 28 "Reserved" 29 "Reserved" 30 "Reserved" 31 "Reserved";
VAL_ 1032 DRIVER_SEATBELT_BUCKLE_DATA 0 "Not Buckled" 1 "Buckled";
VAL_ 1032 DRIVER_SEATBELT_BUCKLE_SECU_DATA 0 "Seat_Belt_Not_Fasten" 1 "Seat_Belt_Fasten" 2 "Undetermined" 3 "Unexpected";
VAL_ 1032 ROW1_P_SEATBELT_BUCKLE_DATA 0 "Not Buckled" 1 "Buckled";
VAL_ 1032 ROW1_P_SEATBELT_BUCKLE_SECU_DATA 0 "Seat_Belt_Not_Fasten" 1 "Seat_Belt_Fasten" 2 "Undetermined" 3 "Unexpected";
VAL_ 1032 TURN_INDICATOR_DRIVER_DMD 0 "IDLE" 1 "LEFT" 2 "RIGHT" 3 "INVALID";
VAL_ 1289 BLINDSPOTDETECTION_DRIVERREQUEST 0 "NotRequested" 1 "Requested ";
VAL_ 1034 VEHICLE_IGNITION_STATUS 0 "Initialization" 1 "IGN_LK" 2 "ACC" 3 "RUN" 4 "START" 5 "RESERVED" 6 "RESERVED" 7 "UNAVAILABLE";
VAL_ 1034 PROPULSION_OFF_REQUEST 0 "Not_Active" 1 "Active";
VAL_ 1034 VEHICLE_MODE_CONFIGURATION 0 "Fitting" 1 "Plant" 2 "Check" 3 "Logistic_mode" 4 "Client" 5 "Show_room" 6 "APV" 7 "INVALID" 8 "Not_used" 9 "Not_used" 10 "Not_used" 11 "Not_used" 12 "Not_used" 13 "Not_used" 14 "Not_used" 15 "Not_used";
VAL_ 1034 DAY_LIGHT_MODE_CMD 0 "Night" 1 "Day";
VAL_ 1550 ESC_TCS_FAILSTATUS 0 "No FAULT" 1 "FAULT";
VAL_ 1550 WHEEL_SPARE_SIZEDETECTION_STATE 0 "No small spare wheel detected" 1 "spare wheel detected";
VAL_ 1055 HOD_FAIL_STATUS 0 "NO FAULT" 3 "FULL FAULT" 1 "CAPACITIVE FAULT" 2 "TORQUE FAULT";
VAL_ 1055 STEERWHEEL_HELD_BY_DRIVER_OPTI 0 "FALSE" 1 "TRUE";
VAL_ 270 PRND_ENGAGED_FOR_DISPLAY 0 "Initialization" 1 "Gear_1st" 2 "Gear_2nd" 3 "Gear_3rd" 4 "Gear_4th" 5 "Gear_5th" 6 "Gear_6th" 7 "Gear_7th" 8 "Gear_8th" 9 "Gear_9th" 10 "Park" 11 "Neutral" 12 "Reverse" 13 "Drive" 14 "Low" 15 "Passive" 16 "Reserved" 17 "Reserved" 18 "Reserved" 19 "Reserved" 20 "Reserved" 21 "Reserved" 22 "Reserved" 23 "Reserved" 24 "Reserved" 25 "Reserved" 26 "Reserved" 27 "Reserved" 28 "Reserved" 29 "Reserved" 30 "Reserved" 31 "SNA";
VAL_ 270 PRND_TARGET_STATE 0 "Neutral" 1 "ForwardGear_1" 2 "ForwardGear_2" 3 "ForwardGear_3" 4 "ForwardGear_4" 5 "ForwardGear_5" 6 "ForwardGear_6" 7 "ForwardGear_7" 8 "ForwardGear_8" 9 "ForwardGear_9" 10 "Parking" 11 "ReverseGear" 12 "Drive" 13 "Low" 14 "Passive" 15 "SNA";
VAL_ 270 SHIFT_LEVER_POSITION_PWT 0 "No_Selection_Active_Or_Available" 1 "Park" 2 "Reverse" 3 "Neutral" 4 "Drive" 5 "Low" 6 "TIP_Autostick" 7 "Plus" 8 "Minus" 9 "Sport" 10 "Reserved" 11 "Reserved" 12 "Reserved" 13 "Reserved" 14 "Reserved" 15 "SNA";
VAL_ 270 LXA_STEERING_STATE_S 0 "Unavailable" 1 "Available" 2 "Active" 3 "Fault";
VAL_ 270 STEERING_ASSIST_STATUS_S 0 "OFF" 1 "ON SBW" 2 "Easy Access SBW" 3 "Alignement SBW" 4 "Paired" 5 "Drive" 6 "Reserved" 7 "Reserved";
VAL_ 270 ACC_STATE_INFO_IN_POWERTRAIN 0 "Shutdown" 1 "Initialization" 2 "Inhibit" 3 "Waiting" 4 "Active not effective" 5 "Active effective" 6 "Reserved" 7 "Failure";
VAL_ 270 CRUISE_CONTROL_STATUS 0 "Inhibit" 1 "Waiting" 2 "Active" 3 "Failure" 4 "Suspended" 5 "Reserved" 6 "Reserved" 7 "Reserved";
VAL_ 1035 PROPULSION_SYSTEM_ACTIVE 0 "FALSE" 1 "TRUE";
VAL_ 1035 DIAGMUX 0 "No communication diagnostic" 1 "Communication diagnostic on";
VAL_ 1035 SHUTDOWN_NTW_FD_CAN14 0 "FALSE" 1 "TRUE";
VAL_ 1035 SHUTDOWN_NTW_FD_CAN5 0 "FALSE" 1 "TRUE";
